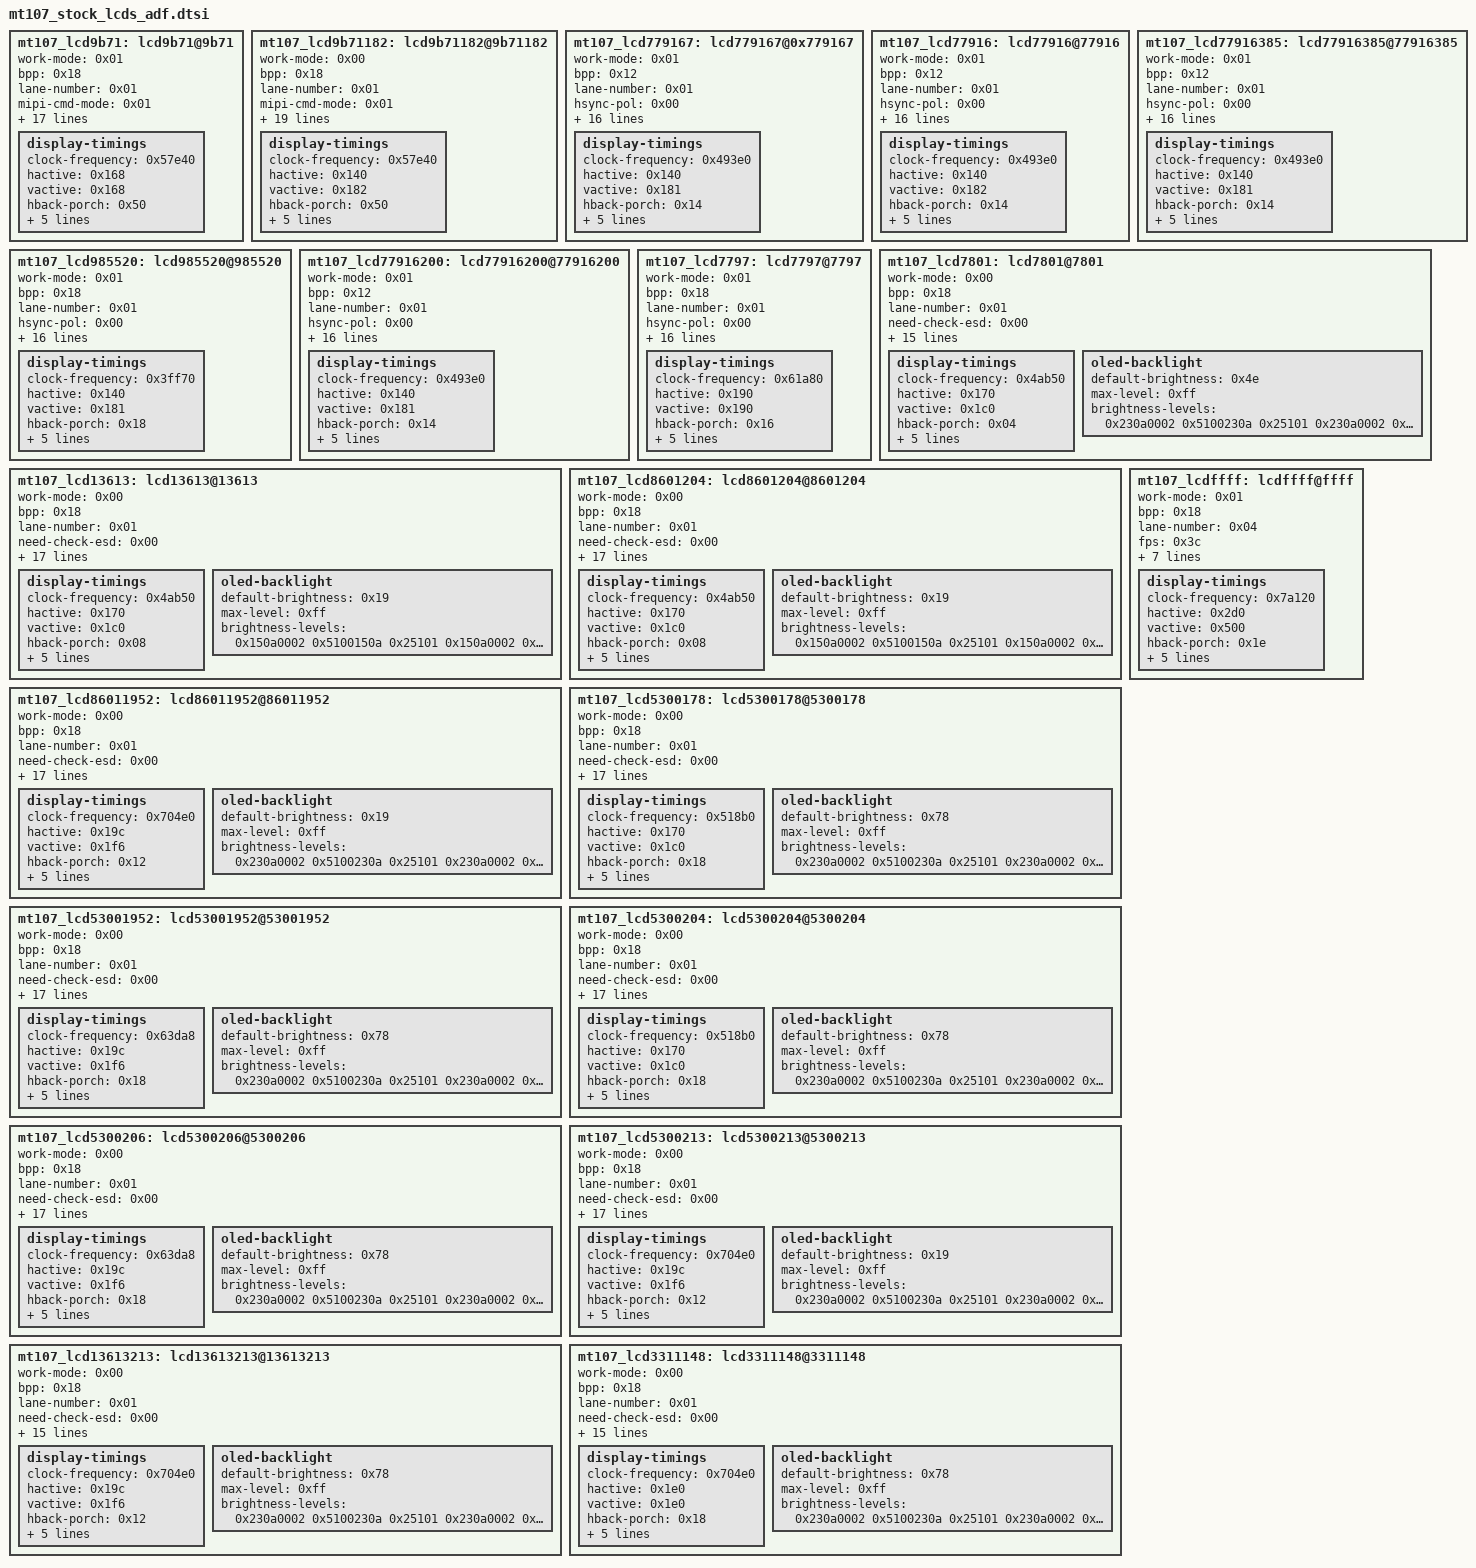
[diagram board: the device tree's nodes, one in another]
// SPDX-License-Identifier: GPL-2.0
/*
 * Stock /lcds panel nodes, generated by devices/stock_lcds_to_dtsi.py
 * from the stock DT; include inside a "lcds" node.
 */

	mt107_lcd9b71: lcd9b71@9b71 {
		work-mode = <0x01>;
		bpp = <0x18>;
		lane-number = <0x01>;
		mipi-cmd-mode = <0x01>;
		hsync-pol = <0x00>;
		vsync-pol = <0x00>;
		de-pol = <0x00>;
		te-pol = <0x00>;
		color-mode-pol = <0x01>;
		shut-down-pol = <0x01>;
		need-check-esd = <0x00>;
		esd-timeout = <0x3e8>;
		fps = <0x3c>;
		panel-name = "lcd_gc9b71_mipi_boe1389";
		power-on-sequence = <0x32 0x01 0x32 0x32 0x00 0x32 0x32 0x01 0xc8>;
		power-off-sequence = <0x32 0x00 0x78>;
		init-data = [05 00 00 01 fe 05 00 00 01 ef 15 00 00 02 80 19 15 00 00 02 81 30 15 00 00 02 82 09 15 00 00 02 83 03 15 00 00 02 84 63 15 00 00 02 89 18 15 00 00 02 8a 40 15 00 00 02 8b 0a 15 00 00 02 3a 07 15 00 00 02 36 00 15 00 00 02 ec 07 39 00 00 08 74 01 68 d8 00 00 4e 00 15 00 00 02 98 3e 15 00 00 02 99 3e 39 00 00 03 a1 01 04 39 00 00 03 a2 01 04 15 00 00 02 cb 02 39 00 00 03 7c b6 24 15 00 00 02 ac 34 15 00 00 02 f6 c8 39 00 00 03 b5 0c 0c 39 00 00 03 eb 01 67 15 00 00 02 b0 81 39 00 00 03 73 10 03 39 00 00 05 60 38 0e 1f 56 39 00 00 05 63 38 10 1f 56 39 00 00 07 64 38 12 72 ea 1f 56 39 00 00 07 66 38 16 72 ee 1f 56 39 00 00 08 68 00 0a ee 0a ee 1c 1c 39 00 00 08 69 00 0a f2 0a f2 1c 1c 39 00 00 21 6e 07 01 1a 00 0b 0b 09 09 13 13 11 11 19 1e 1d 00 00 1d 1e 19 12 12 14 14 0a 0a 0c 0c 00 1a 02 08 39 00 00 08 6c cc 0c cc 84 cc 04 50 15 00 00 02 7d 72 15 00 00 02 35 00 39 00 00 0b 70 02 03 09 07 09 03 09 07 09 03 39 00 00 05 90 06 06 05 06 39 00 00 04 93 45 ff 00 15 00 00 02 c3 10 15 00 00 02 c4 36 15 00 00 02 c9 3f 39 00 00 07 f0 4f 0d 0a 05 00 32 39 00 00 07 f2 4f 0e 09 04 00 31 39 00 00 07 f1 45 d3 7c 2d 2f cf 39 00 00 07 f3 48 d2 7c 2d 2f cf 39 00 00 07 f3 48 d2 7c 2d 2f cf 15 00 00 02 be 11 39 00 00 03 fb 00 00 05 78 00 01 fe 05 78 00 01 ee 05 78 00 01 11 05 78 00 01 29 39 00 00 05 2c 00 00 00 00 39 00 00 05 2c 00 00 00 00];
		sleep-in = [05 0a 00 01 28 05 78 00 01 10];
		sleep-out = [05 78 00 01 11 05 64 00 01 29];

		display-timings {
			clock-frequency = <0x57e40>;
			hactive = <0x168>;
			vactive = <0x168>;
			hback-porch = <0x50>;
			hfront-porch = <0x3c>;
			vback-porch = <0x0c>;
			vfront-porch = <0x08>;
			hsync-len = <0x10>;
			vsync-len = <0x02>;
		};
	};

	mt107_lcd9b71182: lcd9b71182@9b71182 {
		work-mode = <0x00>;
		bpp = <0x18>;
		lane-number = <0x01>;
		mipi-cmd-mode = <0x01>;
		hsync-pol = <0x00>;
		vsync-pol = <0x00>;
		de-pol = <0x00>;
		te-pol = <0x00>;
		color-mode-pol = <0x01>;
		shut-down-pol = <0x01>;
		need-check-esd = <0x00>;
		esd-timeout = <0x7d0>;
		esd-check-reg = <0x0a>;
		esd-return-code = <0x9c>;
		fps = <0x3c>;
		panel-name = "lcd_gc9b71_mipi_boe182";
		power-on-sequence = <0x32 0x01 0x14 0x32 0x00 0x14 0x32 0x01 0x78>;
		power-off-sequence = <0x32 0x00 0x78>;
		init-data = [05 00 00 01 fe 05 00 00 01 ef 15 00 00 02 80 11 15 00 00 02 81 30 15 00 00 02 82 09 15 00 00 02 83 03 15 00 00 02 84 32 15 00 00 02 89 18 15 00 00 02 8a 40 15 00 00 02 8b 0a 15 00 00 02 3a 07 15 00 00 02 36 40 15 00 00 02 ec 07 39 00 00 07 74 01 80 00 00 00 00 15 00 00 02 98 3e 15 00 00 02 99 3e 39 00 00 03 a1 01 04 39 00 00 03 a2 01 04 15 00 00 02 cb 02 39 00 00 03 7c b6 24 15 00 00 02 ac 74 15 00 00 02 f6 80 39 00 00 03 b5 09 09 39 00 00 03 eb 01 81 39 00 00 05 60 38 06 13 56 39 00 00 05 63 38 08 13 56 39 00 00 05 61 3b 1b 58 38 39 00 00 05 62 3b 1b 58 38 39 00 00 07 64 38 0a 73 16 13 56 39 00 00 07 66 38 0b 73 17 13 56 39 00 00 08 68 00 0b 22 0b 22 1c 1c 39 00 00 08 69 00 0b 26 0b 26 1c 1c 39 00 00 03 6a 15 00 39 0a 00 21 6e 08 02 1a 00 12 12 11 11 14 14 13 13 04 19 1e 1d 1d 1e 19 04 0b 0b 0c 0c 09 09 0a 0a 00 1a 01 07 39 00 00 08 6c cc 0c cc 84 cc 04 50 15 00 00 02 7d 72 39 00 00 0b 70 02 03 09 07 09 03 09 07 09 03 39 00 00 05 90 06 06 05 06 39 00 00 04 93 45 ff 00 15 00 00 02 c3 15 15 00 00 02 c4 36 15 00 00 02 c9 3d 39 00 00 07 f0 47 07 0a 0a 00 29 39 00 00 07 f2 47 07 0a 0a 00 29 39 00 00 07 f1 42 91 10 2d 2f 6f 39 00 00 07 f3 42 91 10 2d 2f 6f 39 00 00 05 2a 00 00 01 3f 39 00 00 05 2b 00 00 01 81 05 00 00 01 2c 15 00 00 02 f9 30 15 00 00 02 be 11 39 00 00 03 fb 00 00 15 00 00 03 b4 0a 00 15 00 00 02 35 00 05 00 00 01 fe 05 00 00 01 ef 05 78 00 01 11 05 14 00 01 29 39 00 00 05 2c 00 00 00 00 39 34 00 05 2c 00 00 00 00];
		sleep-in = [05 0a 00 01 28 05 78 00 01 10];
		sleep-out = [05 78 00 01 11 05 64 00 01 29];

		display-timings {
			clock-frequency = <0x57e40>;
			hactive = <0x140>;
			vactive = <0x182>;
			hback-porch = <0x50>;
			hfront-porch = <0x3c>;
			vback-porch = <0x0c>;
			vfront-porch = <0x08>;
			hsync-len = <0x10>;
			vsync-len = <0x02>;
		};
	};

	mt107_lcd779167: lcd779167@0x779167 {
		work-mode = <0x01>;
		bpp = <0x12>;
		lane-number = <0x01>;
		hsync-pol = <0x00>;
		vsync-pol = <0x00>;
		de-pol = <0x00>;
		te-pol = <0x00>;
		color-mode-pol = <0x01>;
		shut-down-pol = <0x01>;
		need-check-esd = <0x00>;
		esd-timeout = <0x3e8>;
		fps = <0x37>;
		panel-name = "lcd_st77916_k7_mipi_boe196";
		power-on-sequence = <0x32 0x01 0x32 0x32 0x00 0x32 0x32 0x01 0x78>;
		power-off-sequence = <0x32 0x00 0x14>;
		init-data = [39 00 00 03 f0 00 08 39 00 00 03 f2 00 08 39 00 00 03 9b 00 51 39 00 00 03 86 00 53 39 00 00 03 f2 00 80 39 00 00 03 f0 00 00 39 00 00 03 f0 00 01 39 00 00 03 f1 00 01 39 00 00 03 b0 00 56 39 00 00 03 b1 00 4d 39 00 00 03 b2 00 24 39 00 00 03 b4 00 66 39 00 00 03 b5 00 44 39 00 00 03 b6 00 8b 39 00 00 03 b7 00 40 39 00 00 03 ba 00 00 39 00 00 03 bb 00 08 39 00 00 03 bc 00 08 39 00 00 03 bd 00 00 39 00 00 03 c0 00 80 39 00 00 03 c1 00 06 39 00 00 03 c2 00 35 39 00 00 03 c3 00 80 39 00 00 03 c4 00 06 39 00 00 03 c5 00 35 39 00 00 03 c6 00 a9 39 00 00 03 c7 00 41 39 00 00 03 c8 00 51 39 00 00 03 c9 00 a9 39 00 00 03 ca 00 41 39 00 00 03 cb 00 51 39 00 00 03 d0 00 d1 39 00 00 03 d1 00 40 39 00 00 03 d2 00 82 39 00 00 04 f5 00 00 a5 39 00 00 03 dd 00 49 39 00 00 03 de 00 49 39 00 00 03 f1 00 10 39 00 00 03 f0 00 00 39 00 00 03 f0 00 02 39 05 00 1d e0 00 f0 00 0a 00 11 00 0c 00 0b 00 08 00 3a 00 54 00 51 00 29 00 16 00 15 00 31 00 34 39 05 00 1d e1 00 f0 00 0a 00 11 00 0b 00 0a 00 07 00 39 00 43 00 4e 00 09 00 15 00 15 00 2e 00 34 39 00 00 03 f0 00 10 39 00 00 03 f3 00 10 39 00 00 03 e0 00 08 39 00 00 03 e1 00 00 39 00 00 03 e2 00 0b 39 00 00 03 e3 00 00 39 00 00 03 e4 00 e0 39 00 00 03 e5 00 06 39 00 00 03 e6 00 21 39 00 00 03 e7 00 10 39 00 00 03 e8 00 8a 39 00 00 03 e9 00 82 39 00 00 03 ea 00 e4 39 00 00 03 eb 00 00 39 00 00 03 ec 00 00 39 00 00 03 ed 00 14 39 00 00 03 ee 00 ff 39 00 00 03 ef 00 00 39 00 00 03 f8 00 ff 39 00 00 03 f9 00 00 39 00 00 03 fa 00 00 39 00 00 03 fb 00 30 39 00 00 03 fc 00 00 39 00 00 03 fd 00 00 39 00 00 03 fe 00 00 39 00 00 03 ff 00 00 39 00 00 03 60 00 50 39 00 00 03 61 00 02 39 00 00 03 62 00 0b 39 00 00 03 63 00 50 39 00 00 03 64 00 04 39 00 00 03 65 00 0b 39 00 00 03 66 00 53 39 00 00 03 67 00 08 39 00 00 03 68 00 0b 39 00 00 03 69 00 53 39 00 00 03 6a 00 0a 39 00 00 03 6b 00 0b 39 00 00 03 70 00 50 39 00 00 03 71 00 01 39 00 00 03 72 00 0b 39 00 00 03 73 00 50 39 00 00 03 74 00 03 39 00 00 03 75 00 0b 39 00 00 03 76 00 53 39 00 00 03 77 00 07 39 00 00 03 78 00 0b 39 00 00 03 79 00 53 39 00 00 03 7a 00 09 39 00 00 03 7b 00 0b 39 00 00 03 80 00 58 39 00 00 03 81 00 00 39 00 00 03 82 00 04 39 00 00 03 83 00 03 39 00 00 03 84 00 0c 39 00 00 03 85 00 00 39 00 00 03 86 00 00 39 00 00 03 87 00 00 39 00 00 03 88 00 58 39 00 00 03 89 00 00 39 00 00 03 8a 00 06 39 00 00 03 8b 00 03 39 00 00 03 8c 00 0e 39 00 00 03 8d 00 00 39 00 00 03 8e 00 00 39 00 00 03 8f 00 00 39 00 00 03 90 00 58 39 00 00 03 91 00 00 39 00 00 03 92 00 08 39 00 00 03 93 00 03 39 00 00 03 94 00 10 39 00 00 03 95 00 00 39 00 00 03 96 00 00 39 00 00 03 97 00 00 39 00 00 03 98 00 58 39 00 00 03 99 00 00 39 00 00 03 9a 00 0a 39 00 00 03 9b 00 03 39 00 00 03 9c 00 12 39 00 00 03 9d 00 00 39 00 00 03 9e 00 00 39 00 00 03 9f 00 00 39 00 00 03 a0 00 58 39 00 00 03 a1 00 00 39 00 00 03 a2 00 03 39 00 00 03 a3 00 03 39 00 00 03 a4 00 0b 39 00 00 03 a5 00 00 39 00 00 03 a6 00 00 39 00 00 03 a7 00 00 39 00 00 03 a8 00 58 39 00 00 03 a9 00 00 39 00 00 03 aa 00 05 39 00 00 03 ab 00 03 39 00 00 03 ac 00 0d 39 00 00 03 ad 00 00 39 00 00 03 ae 00 00 39 00 00 03 af 00 00 39 00 00 03 b0 00 58 39 00 00 03 b1 00 00 39 00 00 03 b2 00 07 39 00 00 03 b3 00 03 39 00 00 03 b4 00 0f 39 00 00 03 b5 00 00 39 00 00 03 b6 00 00 39 00 00 03 b7 00 00 39 00 00 03 b8 00 58 39 00 00 03 b9 00 00 39 00 00 03 ba 00 09 39 00 00 03 bb 00 03 39 00 00 03 bc 00 11 39 00 00 03 bd 00 00 39 00 00 03 be 00 00 39 00 00 03 bf 00 00 39 00 00 03 c0 00 03 39 00 00 03 c1 00 12 39 00 00 03 c2 00 aa 39 00 00 03 c3 00 30 39 00 00 03 c4 00 21 39 00 00 03 c5 00 bb 39 00 00 03 c6 00 64 39 00 00 03 c7 00 55 39 00 00 03 c8 00 46 39 00 00 03 c9 00 77 39 00 00 03 d0 00 03 39 00 00 03 d1 00 12 39 00 00 03 d2 00 aa 39 00 00 03 d3 00 30 39 00 00 03 d4 00 21 39 00 00 03 d5 00 bb 39 00 00 03 d6 00 64 39 00 00 03 d7 00 55 39 00 00 03 d8 00 46 39 00 00 03 d9 00 77 39 00 00 03 f3 00 01 39 00 00 03 f0 00 00 39 00 00 03 f0 00 01 39 00 00 03 f1 00 01 39 00 00 03 a0 00 0b 39 00 00 03 a3 00 2a 39 0a 00 03 a5 00 c3 39 00 00 03 a3 00 2b 39 0a 00 03 a5 00 c3 39 00 00 03 a3 00 2c 39 0a 00 03 a5 00 c3 39 00 00 03 a3 00 2d 39 0a 00 03 a5 00 c3 39 00 00 03 a3 00 2e 39 0a 00 03 a5 00 c3 39 00 00 03 a3 00 2f 39 0a 00 03 a5 00 c3 39 00 00 03 a3 00 30 39 0a 00 03 a5 00 c3 39 00 00 03 a3 00 31 39 0a 00 03 a5 00 c3 39 00 00 03 a3 00 32 39 0a 00 03 a5 00 c3 39 00 00 03 a3 00 33 39 0a 00 03 a5 00 c3 39 00 00 03 a0 00 09 39 00 00 03 f1 00 10 39 0a 00 03 f0 00 00 39 00 00 09 2a 00 00 00 00 00 01 00 3f 39 00 00 09 2b 00 01 00 81 00 01 00 81 39 00 00 03 4d 00 00 39 00 00 03 4e 00 00 39 00 00 03 4f 00 00 39 00 00 03 4c 00 01 39 0a 00 03 4c 00 00 39 00 00 09 2a 00 00 00 00 00 01 00 3f 39 00 00 09 2b 00 00 00 00 00 01 00 80 39 00 00 01 21 39 00 00 03 3a 00 66 39 78 00 01 11 39 2a 00 01 29 39 32 00 01 00];
		sleep-in = [13 0a 00 01 28 13 78 00 01 10];
		sleep-out = [13 78 00 01 11 13 64 00 01 29];

		display-timings {
			clock-frequency = <0x493e0>;
			hactive = <0x140>;
			vactive = <0x181>;
			hback-porch = <0x14>;
			hfront-porch = <0x1e>;
			vback-porch = <0x10>;
			vfront-porch = <0x10>;
			hsync-len = <0x0a>;
			vsync-len = <0x02>;
		};
	};

	mt107_lcd77916: lcd77916@77916 {
		work-mode = <0x01>;
		bpp = <0x12>;
		lane-number = <0x01>;
		hsync-pol = <0x00>;
		vsync-pol = <0x00>;
		de-pol = <0x00>;
		te-pol = <0x00>;
		color-mode-pol = <0x01>;
		shut-down-pol = <0x01>;
		need-check-esd = <0x00>;
		esd-timeout = <0x3e8>;
		fps = <0x32>;
		panel-name = "lcd_st77916_mipi_boe196";
		power-on-sequence = <0x32 0x01 0x32 0x32 0x00 0x32 0x32 0x01 0x78>;
		power-off-sequence = <0x32 0x00 0x14>;
		init-data = <0x39000003 0xf0000839 0x3f2 0x83900 0x39b00 0x51390000 0x3860053 0x39000003 0xf2008039 0x3f0 0x3900 0x3f000 0x1390000 0x3f10001 0x39000003 0xb0005e39 0x3b1 0x3d3900 0x3b200 0x30390000 0x3b40027 0x39000003 0xb5003439 0x3b6 0xa53900 0x3b700 0x20390000 0x3ba0000 0x39000003 0xbb000839 0x3bc 0x83900 0x3bd00 0x390000 0x3c00080 0x39000003 0xc1000b39 0x3c2 0x343900 0x3c300 0x80390000 0x3c4000b 0x39000003 0xc5003439 0x3c6 0xa93900 0x3c700 0x41390000 0x3c80051 0x39000003 0xc900a939 0x3ca 0x413900 0x3cb00 0x51390000 0x3d000d1 0x39000003 0xd1004039 0x3d2 0x833900 0x4f500 0xa53900 0x3dd00 0x2f390000 0x3de002f 0x39000003 0xf1001039 0x3f0 0x3900 0x3f000 0x2390500 0x1de000f0 0xa0010 0xa0009 0x150037 0x33004f 0x380014 0x140032 0x363905 0x1de100 0xf0000900 0xf000a00 0x9002500 0x37003300 0x4f003700 0x13001400 0x31003539 0x3f0 0x103900 0x3f300 0x10390000 0x3e0000c 0x39000003 0xe1000039 0x3e2 0x3900 0x3e300 0x390000 0x3e400e0 0x39000003 0xe5000639 0x3e6 0x213900 0x3e700 0x10390000 0x3e80085 0x39000003 0xe9008339 0x3ea 0x163900 0x3eb00 0x390000 0x3ec0000 0x39000003 0xed001439 0x3ee 0xff3900 0x3ef00 0x390000 0x3f800ff 0x39000003 0xf9000039 0x3fa 0x3900 0x3fb00 0x30390000 0x3fc0000 0x39000003 0xfd000039 0x3fe 0x3900 0x3ff00 0x390000 0x3600043 0x39000003 0x61001a39 0x362 0x403900 0x36300 0x40390000 0x3640002 0x39000003 0x65000039 0x366 0x403900 0x36700 0x3390000 0x3680000 0x39000003 0x69000039 0x36a 0x3900 0x36b00 0x390000 0x3700043 0x39000003 0x71001a39 0x372 0x403900 0x37300 0x40390000 0x3740002 0x39000003 0x75000039 0x376 0x403900 0x37700 0x3390000 0x3780000 0x39000003 0x79000039 0x37a 0x3900 0x37b00 0x390000 0x3800048 0x39000003 0x81000039 0x382 0x73900 0x38300 0x3390000 0x3840017 0x39000003 0x85000039 0x386 0x3900 0x38700 0x390000 0x3880048 0x39000003 0x89000039 0x38a 0x93900 0x38b00 0x3390000 0x38c0019 0x39000003 0x8d000039 0x38e 0x3900 0x38f00 0x390000 0x3900048 0x39000003 0x91000039 0x392 0xb3900 0x39300 0x3390000 0x3940013 0x39000003 0x95000039 0x396 0x3900 0x39700 0x390000 0x3980048 0x39000003 0x99000039 0x39a 0xd3900 0x39b00 0x3390000 0x39c0015 0x39000003 0x9d000039 0x39e 0x3900 0x39f00 0x390000 0x3a00048 0x39000003 0xa1000039 0x3a2 0x63900 0x3a300 0x3390000 0x3a40016 0x39000003 0xa5000039 0x3a6 0x3900 0x3a700 0x390000 0x3a80048 0x39000003 0xa9000039 0x3aa 0x83900 0x3ab00 0x3390000 0x3ac0018 0x39000003 0xad000039 0x3ae 0x3900 0x3af00 0x390000 0x3b00048 0x39000003 0xb1000039 0x3b2 0xa3900 0x3b300 0x3390000 0x3b40012 0x39000003 0xb5000039 0x3b6 0x3900 0x3b700 0x390000 0x3b80048 0x39000003 0xb9000039 0x3ba 0xc3900 0x3bb00 0x3390000 0x3bc0014 0x39000003 0xbd000039 0x3be 0x3900 0x3bf00 0x390000 0x3c00045 0x39000003 0xc1005439 0x3c2 0x673900 0x3c300 0x76390000 0x3c40088 0x39000003 0xc500aa39 0x3c6 0x223900 0x3c700 0xbb390000 0x3c80000 0x39000003 0xc9009939 0x3d0 0x453900 0x3d100 0x54390000 0x3d20067 0x39000003 0xd3007639 0x3d4 0x883900 0x3d500 0xaa390000 0x3d60011 0x39000003 0xd700bb39 0x3d8 0x3900 0x3d900 0x99390000 0x3f30001 0x39000003 0xf0000039 0x3f0 0x13900 0x3f100 0x1390000 0x3a0000b 0x39000003 0xa3002a39 0xa0003a5 0xc33900 0x3a300 0x2b390a00 0x3a500c3 0x39000003 0xa3002c39 0xa0003a5 0xc33900 0x3a300 0x2d390a00 0x3a500c3 0x39000003 0xa3002e39 0xa0003a5 0xc33900 0x3a300 0x2f390a00 0x3a500c3 0x39000003 0xa3003039 0xa0003a5 0xc33900 0x3a300 0x31390a00 0x3a500c3 0x39000003 0xa3003239 0xa0003a5 0xc33900 0x3a300 0x33390a00 0x3a500c3 0x39000003 0xa0000939 0x3f1 0x10390a 0x3f000 0x390000 0x92a0000 0x01 0x3f3900 0x92b00 0x1008200 0x1008239 0x34d 0x3900 0x34e00 0x390000 0x34f0000 0x390a0003 0x4c000139 0x92a 0x00 0x1003f 0x39000009 0x2b000000 0x100 0x81050000 0x1213900 0x33a00 0x66057800 0x111052a 0x12905 0x32000100>;
		sleep-in = [05 0a 00 01 28 05 78 00 01 10];
		sleep-out = [05 78 00 01 11 05 64 00 01 29];

		display-timings {
			clock-frequency = <0x493e0>;
			hactive = <0x140>;
			vactive = <0x182>;
			hback-porch = <0x14>;
			hfront-porch = <0x1e>;
			vback-porch = <0x10>;
			vfront-porch = <0x10>;
			hsync-len = <0x0a>;
			vsync-len = <0x02>;
		};
	};

	mt107_lcd77916385: lcd77916385@77916385 {
		work-mode = <0x01>;
		bpp = <0x12>;
		lane-number = <0x01>;
		hsync-pol = <0x00>;
		vsync-pol = <0x00>;
		de-pol = <0x00>;
		te-pol = <0x00>;
		color-mode-pol = <0x01>;
		shut-down-pol = <0x01>;
		need-check-esd = <0x00>;
		esd-timeout = <0x3e8>;
		fps = <0x37>;
		panel-name = "lcd_st77916_mipi_cto200";
		power-on-sequence = <0x32 0x01 0x32 0x32 0x00 0x32 0x32 0x01 0x78>;
		power-off-sequence = <0x32 0x00 0x14>;
		init-data = [39 00 00 03 f0 00 08 39 00 00 03 f2 00 08 39 00 00 03 9b 00 51 39 00 00 03 86 00 53 39 00 00 03 f2 00 80 39 00 00 03 f0 00 00 39 00 00 03 f0 00 28 39 00 00 03 f2 00 28 39 00 00 03 83 00 e0 39 00 00 03 84 00 61 39 00 00 03 f2 00 82 39 00 00 03 f0 00 00 39 00 00 03 f0 00 01 39 00 00 03 f1 00 01 39 00 00 03 70 00 bf 39 00 00 03 b0 00 56 39 00 00 03 b1 00 4d 39 00 00 03 b2 00 24 39 00 00 03 b4 00 66 39 00 00 03 b5 00 44 39 00 00 03 b6 00 8b 39 00 00 03 b7 00 40 39 00 00 03 b8 00 05 39 00 00 03 ba 00 00 39 00 00 03 bb 00 08 39 00 00 03 bc 00 08 39 00 00 03 bd 00 00 39 00 00 03 c0 00 80 39 00 00 03 c1 00 08 39 00 00 03 c2 00 35 39 00 00 03 c3 00 80 39 00 00 03 c4 00 08 39 00 00 03 c5 00 35 39 00 00 03 c6 00 a9 39 00 00 03 c7 00 41 39 00 00 03 c8 00 51 39 00 00 03 c9 00 a9 39 00 00 03 ca 00 41 39 00 00 03 cb 00 51 39 00 00 03 d0 00 d1 39 00 00 03 d1 00 40 39 00 00 03 d2 00 82 39 00 00 04 f5 00 00 a5 39 00 00 03 dd 00 49 39 00 00 03 de 00 49 39 00 00 03 f1 00 10 39 00 00 03 f0 00 00 39 00 00 03 f0 00 02 39 05 00 1d e0 00 f0 00 0a 00 11 00 0c 00 0b 00 08 00 3a 00 54 00 51 00 29 00 16 00 15 00 31 00 34 39 05 00 1d e1 00 f0 00 0a 00 11 00 0b 00 0a 00 07 00 39 00 43 00 4e 00 09 00 15 00 15 00 2e 00 34 39 00 00 03 f0 00 10 39 00 00 03 f3 00 10 39 00 00 03 e0 00 08 39 00 00 03 e1 00 00 39 00 00 03 e2 00 0b 39 00 00 03 e3 00 00 39 00 00 03 e4 00 e0 39 00 00 03 e5 00 06 39 00 00 03 e6 00 21 39 00 00 03 e7 00 10 39 00 00 03 e8 00 8a 39 00 00 03 e9 00 82 39 00 00 03 ea 00 e4 39 00 00 03 eb 00 00 39 00 00 03 ec 00 00 39 00 00 03 ed 00 14 39 00 00 03 ee 00 ff 39 00 00 03 ef 00 00 39 00 00 03 f8 00 ff 39 00 00 03 f9 00 00 39 00 00 03 fa 00 00 39 00 00 03 fb 00 30 39 00 00 03 fc 00 00 39 00 00 03 fd 00 00 39 00 00 03 fe 00 00 39 00 00 03 ff 00 00 39 00 00 03 60 00 50 39 00 00 03 61 00 02 39 00 00 03 62 00 0b 39 00 00 03 63 00 50 39 00 00 03 64 00 04 39 00 00 03 65 00 0b 39 00 00 03 66 00 53 39 00 00 03 67 00 08 39 00 00 03 68 00 0b 39 00 00 03 69 00 53 39 00 00 03 6a 00 0a 39 00 00 03 6b 00 0b 39 00 00 03 70 00 50 39 00 00 03 71 00 01 39 00 00 03 72 00 0b 39 00 00 03 73 00 50 39 00 00 03 74 00 03 39 00 00 03 75 00 0b 39 00 00 03 76 00 53 39 00 00 03 77 00 07 39 00 00 03 78 00 0b 39 00 00 03 79 00 53 39 00 00 03 7a 00 09 39 00 00 03 7b 00 0b 39 00 00 03 80 00 58 39 00 00 03 81 00 00 39 00 00 03 82 00 04 39 00 00 03 83 00 03 39 00 00 03 84 00 0c 39 00 00 03 85 00 00 39 00 00 03 86 00 00 39 00 00 03 87 00 00 39 00 00 03 88 00 58 39 00 00 03 89 00 00 39 00 00 03 8a 00 06 39 00 00 03 8b 00 03 39 00 00 03 8c 00 0e 39 00 00 03 8d 00 00 39 00 00 03 8e 00 00 39 00 00 03 8f 00 00 39 00 00 03 90 00 58 39 00 00 03 91 00 00 39 00 00 03 92 00 08 39 00 00 03 93 00 03 39 00 00 03 94 00 10 39 00 00 03 95 00 00 39 00 00 03 96 00 00 39 00 00 03 97 00 00 39 00 00 03 98 00 58 39 00 00 03 99 00 00 39 00 00 03 9a 00 0a 39 00 00 03 9b 00 03 39 00 00 03 9c 00 12 39 00 00 03 9d 00 00 39 00 00 03 9e 00 00 39 00 00 03 9f 00 00 39 00 00 03 a0 00 58 39 00 00 03 a1 00 00 39 00 00 03 a2 00 03 39 00 00 03 a3 00 03 39 00 00 03 a4 00 0b 39 00 00 03 a5 00 00 39 00 00 03 a6 00 00 39 00 00 03 a7 00 00 39 00 00 03 a8 00 58 39 00 00 03 a9 00 00 39 00 00 03 aa 00 05 39 00 00 03 ab 00 03 39 00 00 03 ac 00 0d 39 00 00 03 ad 00 00 39 00 00 03 ae 00 00 39 00 00 03 af 00 00 39 00 00 03 b0 00 58 39 00 00 03 b1 00 00 39 00 00 03 b2 00 07 39 00 00 03 b3 00 03 39 00 00 03 b4 00 0f 39 00 00 03 b5 00 00 39 00 00 03 b6 00 00 39 00 00 03 b7 00 00 39 00 00 03 b8 00 58 39 00 00 03 b9 00 00 39 00 00 03 ba 00 09 39 00 00 03 bb 00 03 39 00 00 03 bc 00 11 39 00 00 03 bd 00 00 39 00 00 03 be 00 00 39 00 00 03 bf 00 00 39 00 00 03 c0 00 03 39 00 00 03 c1 00 12 39 00 00 03 c2 00 aa 39 00 00 03 c3 00 30 39 00 00 03 c4 00 21 39 00 00 03 c5 00 bb 39 00 00 03 c6 00 64 39 00 00 03 c7 00 55 39 00 00 03 c8 00 46 39 00 00 03 c9 00 77 39 00 00 03 d0 00 03 39 00 00 03 d1 00 12 39 00 00 03 d2 00 aa 39 00 00 03 d3 00 30 39 00 00 03 d4 00 21 39 00 00 03 d5 00 bb 39 00 00 03 d6 00 64 39 00 00 03 d7 00 55 39 00 00 03 d8 00 46 39 00 00 03 d9 00 77 39 00 00 03 f3 00 01 39 00 00 03 f0 00 00 39 00 00 03 f0 00 01 39 00 00 03 f1 00 01 39 00 00 03 a0 00 0b 39 00 00 03 a3 00 2a 39 0a 00 03 a5 00 c3 39 00 00 03 a3 00 2b 39 0a 00 03 a5 00 c3 39 00 00 03 a3 00 2c 39 0a 00 03 a5 00 c3 39 00 00 03 a3 00 2d 39 0a 00 03 a5 00 c3 39 00 00 03 a3 00 2e 39 0a 00 03 a5 00 c3 39 00 00 03 a3 00 2f 39 0a 00 03 a5 00 c3 39 00 00 03 a3 00 30 39 0a 00 03 a5 00 c3 39 00 00 03 a3 00 31 39 0a 00 03 a5 00 c3 39 00 00 03 a3 00 32 39 0a 00 03 a5 00 c3 39 00 00 03 a3 00 33 39 0a 00 03 a5 00 c3 39 00 00 03 a0 00 09 39 00 00 03 f1 00 10 39 0a 00 03 f0 00 00 39 00 00 09 2a 00 00 00 00 00 01 00 3f 39 00 00 09 2b 00 01 00 81 00 01 00 81 39 00 00 03 4d 00 00 39 00 00 03 4e 00 00 39 00 00 03 4f 00 00 39 0a 00 03 4c 00 01 39 00 00 03 4c 00 00 39 00 00 09 2a 00 00 00 00 00 01 00 3f 39 00 00 09 2b 00 00 00 00 00 01 00 80 05 00 00 01 21 39 00 00 03 3a 00 66 05 78 00 01 11 05 2a 00 01 29 05 32 00 01 00];
		sleep-in = [05 0a 00 01 28 05 78 00 01 10];
		sleep-out = [05 78 00 01 11 05 64 00 01 29];

		display-timings {
			clock-frequency = <0x493e0>;
			hactive = <0x140>;
			vactive = <0x181>;
			hback-porch = <0x14>;
			hfront-porch = <0x1e>;
			vback-porch = <0x10>;
			vfront-porch = <0x10>;
			hsync-len = <0x0a>;
			vsync-len = <0x02>;
		};
	};

	mt107_lcd985520: lcd985520@985520 {
		work-mode = <0x01>;
		bpp = <0x18>;
		lane-number = <0x01>;
		hsync-pol = <0x00>;
		vsync-pol = <0x00>;
		de-pol = <0x00>;
		te-pol = <0x00>;
		color-mode-pol = <0x01>;
		shut-down-pol = <0x01>;
		need-check-esd = <0x00>;
		esd-timeout = <0x3e8>;
		fps = <0x3c>;
		panel-name = "lcd_jd9855_oled_cto20_mipi";
		power-on-sequence = <0x32 0x01 0x32 0x32 0x00 0x32 0x32 0x01 0x78>;
		power-off-sequence = <0x32 0x00 0x14>;
		init-data = [23 00 00 02 de 00 29 00 00 03 df 98 55 23 00 00 02 b2 2f 29 00 00 05 b7 01 33 01 5b 29 00 00 07 bb 1b 64 c2 33 3e f3 29 00 00 05 bc 00 18 f3 c0 29 00 00 03 c0 22 c1 29 00 00 0c c3 00 02 2a 0b 08 47 08 04 62 30 30 29 00 00 0c c4 40 00 a8 81 3f 07 04 16 3f 07 04 29 05 00 21 c8 3f 31 28 23 22 23 1d 1d 1b 1b 17 0d 09 06 02 02 3f 31 28 23 22 23 1d 1d 1b 1b 17 0d 09 06 02 02 29 00 00 03 d3 28 13 29 00 00 03 d7 1b 30 29 00 00 07 d9 00 00 ff 00 f0 00 23 00 00 02 de 01 29 00 00 09 b7 13 e7 64 39 06 36 18 18 23 00 00 02 be 00 29 00 00 05 c1 00 4a 90 08 29 00 00 05 c2 00 16 da e7 29 00 00 07 c7 00 00 02 7c 02 7c 29 00 00 07 c8 00 00 03 01 39 0a 29 00 00 06 c9 12 10 1f 00 02 29 00 00 06 ca 1e 04 06 08 0a 29 00 00 06 cb 13 11 1f 01 03 29 00 00 06 cc 1e 05 07 09 0b 29 00 00 06 cd 01 03 1f 13 11 29 00 00 06 ce 1e 09 07 05 0b 29 00 00 06 cf 00 02 1f 12 10 29 00 00 06 d0 1e 08 06 04 0a 29 00 00 06 d1 04 30 bf 0a 30 29 00 00 07 d3 3c 05 06 01 00 00 23 00 00 02 d4 07 29 00 00 08 d5 10 10 07 07 0f 94 26 29 00 00 04 d6 00 00 40 29 00 00 08 d7 03 8f 20 00 07 00 c0 23 00 00 02 de 02 23 00 00 02 b6 1c 23 00 00 02 de 00 23 00 00 02 4d 00 23 00 00 02 4e 00 23 00 00 02 4f 00 23 0a 00 02 4c 01 23 00 00 02 4c 00 29 00 00 05 2a 00 00 01 3f 29 00 00 05 2b 00 00 01 80 23 00 00 02 35 00 23 00 00 02 3a 77 13 78 00 01 11 13 0a 00 01 29];
		sleep-in = [05 0a 00 01 28 05 78 00 01 10];
		sleep-out = [05 78 00 01 11 05 64 00 01 29];

		display-timings {
			clock-frequency = <0x3ff70>;
			hactive = <0x140>;
			vactive = <0x181>;
			hback-porch = <0x18>;
			hfront-porch = <0x20>;
			vback-porch = <0x04>;
			vfront-porch = <0x08>;
			hsync-len = <0x04>;
			vsync-len = <0x02>;
		};
	};

	mt107_lcd77916200: lcd77916200@77916200 {
		work-mode = <0x01>;
		bpp = <0x12>;
		lane-number = <0x01>;
		hsync-pol = <0x00>;
		vsync-pol = <0x00>;
		de-pol = <0x00>;
		te-pol = <0x00>;
		color-mode-pol = <0x01>;
		shut-down-pol = <0x01>;
		need-check-esd = <0x00>;
		esd-timeout = <0x3e8>;
		fps = <0x37>;
		panel-name = "lcd_st77916_mipi_boe200";
		power-on-sequence = <0x32 0x01 0x32 0x32 0x00 0x32 0x32 0x01 0x78>;
		power-off-sequence = <0x32 0x00 0x14>;
		init-data = [39 00 00 03 f0 00 28 39 00 00 03 f2 00 28 39 00 00 03 7c 00 d1 39 00 00 03 83 00 e0 39 00 00 03 84 00 61 39 00 00 03 f2 00 82 39 00 00 03 f0 00 00 39 00 00 03 f0 00 01 39 00 00 03 f1 00 01 39 00 00 03 b0 00 4b 39 00 00 03 b1 00 40 39 00 00 03 b2 00 25 39 00 00 03 b4 00 44 39 00 00 03 b5 00 34 39 00 00 03 b6 00 a4 39 00 00 03 b7 00 30 39 00 00 03 ba 00 00 39 00 00 03 bb 00 08 39 00 00 03 bc 00 08 39 00 00 03 bd 00 00 39 00 00 03 c0 00 80 39 00 00 03 c1 00 0b 39 00 00 03 c2 00 35 39 00 00 03 c3 00 80 39 00 00 03 c4 00 0b 39 00 00 03 c5 00 35 39 00 00 03 c6 00 a9 39 00 00 03 c7 00 41 39 00 00 03 c8 00 01 39 00 00 03 c9 00 a9 39 00 00 03 ca 00 41 39 00 00 03 cb 00 01 39 00 00 03 d0 00 d1 39 00 00 03 d1 00 40 39 00 00 03 d2 00 81 39 00 00 04 f5 00 00 a5 39 00 00 03 f1 00 10 39 00 00 03 f0 00 00 39 00 00 03 f0 00 02 39 05 00 1d e0 00 f0 00 09 00 0f 00 0a 00 0a 00 17 00 36 00 44 00 4d 00 38 00 13 00 14 00 2f 00 34 39 05 00 1d e1 00 f0 00 09 00 0f 00 0a 00 09 00 06 00 35 00 33 00 4c 00 37 00 13 00 14 00 2f 00 34 39 00 00 03 f0 00 10 39 00 00 03 f3 00 10 39 00 00 03 e0 00 0d 39 00 00 03 e1 00 00 39 00 00 03 e2 00 00 39 00 00 03 e3 00 00 39 00 00 03 e4 00 e0 39 00 00 03 e5 00 06 39 00 00 03 e6 00 21 39 00 00 03 e7 00 00 39 00 00 03 e8 00 85 39 00 00 03 e9 00 62 39 00 00 03 ea 00 dc 39 00 00 03 eb 00 00 39 00 00 03 ec 00 20 39 00 00 03 ed 00 14 39 00 00 03 ee 00 ff 39 00 00 03 ef 00 00 39 00 00 03 f8 00 ff 39 00 00 03 f9 00 00 39 00 00 03 fa 00 00 39 00 00 03 fb 00 30 39 00 00 03 fc 00 00 39 00 00 03 fd 00 00 39 00 00 03 fe 00 00 39 00 00 03 ff 00 00 39 00 00 03 60 00 20 39 00 00 03 61 00 02 39 00 00 03 62 00 80 39 00 00 03 63 00 40 39 00 00 03 64 00 06 39 00 00 03 65 00 00 39 00 00 03 66 00 00 39 00 00 03 67 00 00 39 00 00 03 68 00 00 39 00 00 03 69 00 23 39 00 00 03 6a 00 15 39 00 00 03 6b 00 00 39 00 00 03 70 00 20 39 00 00 03 71 00 02 39 00 00 03 72 00 80 39 00 00 03 73 00 40 39 00 00 03 74 00 05 39 00 00 03 75 00 00 39 00 00 03 76 00 00 39 00 00 03 77 00 00 39 00 00 03 78 00 00 39 00 00 03 79 00 23 39 00 00 03 7a 00 15 39 00 00 03 7b 00 00 39 00 00 03 80 00 48 39 00 00 03 81 00 00 39 00 00 03 82 00 08 39 00 00 03 83 00 03 39 00 00 03 84 00 18 39 00 00 03 85 00 00 39 00 00 03 86 00 00 39 00 00 03 87 00 00 39 00 00 03 88 00 48 39 00 00 03 89 00 00 39 00 00 03 8a 00 0a 39 00 00 03 8b 00 03 39 00 00 03 8c 00 12 39 00 00 03 8d 00 00 39 00 00 03 8e 00 00 39 00 00 03 8f 00 00 39 00 00 03 90 00 48 39 00 00 03 91 00 00 39 00 00 03 92 00 0c 39 00 00 03 93 00 03 39 00 00 03 94 00 14 39 00 00 03 95 00 00 39 00 00 03 96 00 00 39 00 00 03 97 00 00 39 00 00 03 98 00 48 39 00 00 03 99 00 00 39 00 00 03 9a 00 0e 39 00 00 03 9b 00 03 39 00 00 03 9c 00 16 39 00 00 03 9d 00 00 39 00 00 03 9e 00 00 39 00 00 03 9f 00 00 39 00 00 03 a0 00 48 39 00 00 03 a1 00 00 39 00 00 03 a2 00 07 39 00 00 03 a3 00 03 39 00 00 03 a4 00 17 39 00 00 03 a5 00 00 39 00 00 03 a6 00 00 39 00 00 03 a7 00 00 39 00 00 03 a8 00 48 39 00 00 03 a9 00 00 39 00 00 03 aa 00 09 39 00 00 03 ab 00 03 39 00 00 03 ac 00 11 39 00 00 03 ad 00 00 39 00 00 03 ae 00 00 39 00 00 03 af 00 00 39 00 00 03 b0 00 48 39 00 00 03 b1 00 00 39 00 00 03 b2 00 0b 39 00 00 03 b3 00 03 39 00 00 03 b4 00 13 39 00 00 03 b5 00 00 39 00 00 03 b6 00 00 39 00 00 03 b7 00 00 39 00 00 03 b8 00 48 39 00 00 03 b9 00 00 39 00 00 03 ba 00 0d 39 00 00 03 bb 00 03 39 00 00 03 bc 00 15 39 00 00 03 bd 00 00 39 00 00 03 be 00 00 39 00 00 03 bf 00 00 39 00 00 03 c0 00 75 39 00 00 03 c1 00 44 39 00 00 03 c2 00 57 39 00 00 03 c3 00 66 39 00 00 03 c4 00 aa 39 00 00 03 c5 00 11 39 00 00 03 c6 00 00 39 00 00 03 c7 00 88 39 00 00 03 c8 00 99 39 00 00 03 c9 00 bb 39 00 00 03 d0 00 75 39 00 00 03 d1 00 44 39 00 00 03 d2 00 57 39 00 00 03 d3 00 66 39 00 00 03 d4 00 aa 39 00 00 03 d5 00 11 39 00 00 03 d6 00 00 39 00 00 03 d7 00 88 39 00 00 03 d8 00 99 39 00 00 03 d9 00 bb 39 00 00 03 f3 00 01 39 00 00 03 f0 00 00 05 00 00 01 21 39 00 00 03 3a 00 66 05 78 00 01 11 05 2a 00 01 29 05 32 00 01 00];
		sleep-in = [05 0a 00 01 28 05 78 00 01 10];
		sleep-out = [05 78 00 01 11 05 64 00 01 29];

		display-timings {
			clock-frequency = <0x493e0>;
			hactive = <0x140>;
			vactive = <0x181>;
			hback-porch = <0x14>;
			hfront-porch = <0x1e>;
			vback-porch = <0x10>;
			vfront-porch = <0x10>;
			hsync-len = <0x0a>;
			vsync-len = <0x02>;
		};
	};

	mt107_lcd7797: lcd7797@7797 {
		work-mode = <0x01>;
		bpp = <0x18>;
		lane-number = <0x01>;
		hsync-pol = <0x00>;
		vsync-pol = <0x00>;
		de-pol = <0x00>;
		te-pol = <0x00>;
		color-mode-pol = <0x01>;
		shut-down-pol = <0x01>;
		need-check-esd = <0x00>;
		esd-timeout = <0x3e8>;
		fps = <0x3c>;
		panel-name = "lcd_st7797_mipi";
		power-on-sequence = <0x32 0x01 0x05 0x32 0x00 0x05 0x32 0x01 0x14>;
		power-off-sequence = <0x32 0x00 0x14>;
		init-data = [23 00 00 02 f0 c3 23 00 00 02 f0 96 23 00 00 02 f0 a5 29 00 00 05 c1 bb 02 0f 0b 29 00 00 05 c2 bb 02 0f 0b 29 00 00 05 c3 11 03 24 01 29 00 00 05 c4 11 03 24 01 23 00 00 02 c5 2e 29 00 00 0f e0 f0 05 0a 0c 0a 07 34 73 4b 0e 1b 19 29 2a 29 00 00 0f e1 f0 05 0a 0c 0a 06 33 03 4c 0e 1c 1a 29 2a 29 00 00 03 e4 c8 20 29 00 00 0d e5 0f f5 00 11 22 25 10 77 77 77 44 44 29 00 00 0d e6 0f f5 00 11 22 25 10 22 22 22 22 22 29 00 00 08 e7 00 77 1f cc 2a 80 33 29 00 00 08 ec 00 55 00 00 00 49 22 23 00 00 02 ed c3 29 00 00 03 e4 08 2f 23 00 00 02 b2 10 23 00 00 02 b3 02 23 00 00 02 b4 02 29 00 00 05 b5 00 54 00 54 29 00 00 03 b6 c7 31 29 00 00 08 ba 5b aa 02 00 21 01 00 29 00 00 09 bb 00 28 00 28 08 07 07 04 29 00 00 09 bc 00 36 00 28 08 07 07 04 29 00 00 0c bd 77 ff ff ff ba ab ff ff 16 ff 02 29 00 00 04 a4 c0 4a e0 29 00 00 0a a5 20 12 40 01 00 06 2a 0a 00 29 00 00 0a a6 20 12 40 01 00 06 2a 0a 00 23 00 00 02 d9 22 13 00 00 01 21 23 00 00 02 35 00 23 00 00 02 36 0c 23 00 00 02 3a 07 23 78 00 02 11 00 23 78 00 02 29 00];
		sleep-in = [13 0a 00 01 28 13 78 00 01 10];
		sleep-out = [13 78 00 01 11 13 64 00 01 29];

		display-timings {
			clock-frequency = <0x61a80>;
			hactive = <0x190>;
			vactive = <0x190>;
			hback-porch = <0x16>;
			hfront-porch = <0x16>;
			vback-porch = <0x06>;
			vfront-porch = <0x06>;
			hsync-len = <0x0a>;
			vsync-len = <0x02>;
		};
	};

	mt107_lcd7801: lcd7801@7801 {
		work-mode = <0x00>;
		bpp = <0x18>;
		lane-number = <0x01>;
		need-check-esd = <0x00>;
		esd-timeout = <0x7d0>;
		esd-check-reg = <0x0a>;
		esd-return-code = <0x9c>;
		fps = <0x3c>;
		width-mm = <0x44>;
		height-mm = <0x79>;
		panel-name = "lcd_st7801_oled204_mipi";
		power-on-sequence = <0x21 0x01 0x14 0x32 0x01 0x14 0x32 0x00 0x14 0x32 0x01 0x32>;
		power-off-sequence = <0x32 0x00 0x14 0x21 0x00 0x14>;
		init-data = <0x130a0001 0x11230000 0x2350023 0x253 0x20230000 0x2510013 0x14000129>;
		sleep-in = [13 0a 00 01 28 13 78 00 01 10];
		sleep-out = [13 78 00 01 11 13 32 00 01 29];

		display-timings {
			clock-frequency = <0x4ab50>;
			hactive = <0x170>;
			vactive = <0x1c0>;
			hback-porch = <0x04>;
			hfront-porch = <0x08>;
			vback-porch = <0x04>;
			vfront-porch = <0x08>;
			hsync-len = <0x02>;
			vsync-len = <0x02>;
		};

		oled-backlight {
			default-brightness = <0x4e>;
			max-level = <0xff>;
			brightness-levels = <0x230a0002 0x5100230a 0x25101 0x230a0002 0x5102230a 0x25103 0x230a0002 0x5104230a 0x25105 0x230a0002 0x5106230a 0x25107 0x230a0002 0x5108230a 0x25109 0x230a0002 0x510a230a 0x2510b 0x230a0002 0x510c230a 0x2510d 0x230a0002 0x510e230a 0x2510f 0x230a0002 0x5110230a 0x25111 0x230a0002 0x5112230a 0x25113 0x230a0002 0x5114230a 0x25115 0x230a0002 0x5116230a 0x25117 0x230a0002 0x5118230a 0x25119 0x230a0002 0x511a230a 0x2511b 0x230a0002 0x511c230a 0x2511d 0x230a0002 0x511e230a 0x2511f 0x230a0002 0x5120230a 0x25121 0x230a0002 0x5122230a 0x25123 0x230a0002 0x5124230a 0x25125 0x230a0002 0x5126230a 0x25127 0x230a0002 0x5128230a 0x25129 0x230a0002 0x512a230a 0x2512b 0x230a0002 0x512c230a 0x2512d 0x230a0002 0x512e230a 0x2512f 0x230a0002 0x5130230a 0x25131 0x230a0002 0x5132230a 0x25133 0x230a0002 0x5134230a 0x25135 0x230a0002 0x5136230a 0x25137 0x230a0002 0x5138230a 0x25139 0x230a0002 0x513a230a 0x2513b 0x230a0002 0x513c230a 0x2513d 0x230a0002 0x513e230a 0x2513f 0x230a0002 0x5140230a 0x25141 0x230a0002 0x5142230a 0x25143 0x230a0002 0x5144230a 0x25145 0x230a0002 0x5146230a 0x25147 0x230a0002 0x5148230a 0x25149 0x230a0002 0x514a230a 0x2514b 0x230a0002 0x514c230a 0x2514d 0x230a0002 0x514e230a 0x2514f 0x230a0002 0x5150230a 0x25151 0x230a0002 0x5152230a 0x25153 0x230a0002 0x5154230a 0x25155 0x230a0002 0x5156230a 0x25157 0x230a0002 0x5158230a 0x25159 0x230a0002 0x515a230a 0x2515b 0x230a0002 0x515c230a 0x2515d 0x230a0002 0x515e230a 0x2515f 0x230a0002 0x5160230a 0x25161 0x230a0002 0x5162230a 0x25163 0x230a0002 0x5164230a 0x25165 0x230a0002 0x5166230a 0x25167 0x230a0002 0x5168230a 0x25169 0x230a0002 0x516a230a 0x2516b 0x230a0002 0x516c230a 0x2516d 0x230a0002 0x516e230a 0x2516f 0x230a0002 0x5170230a 0x25171 0x230a0002 0x5172230a 0x25173 0x230a0002 0x5174230a 0x25175 0x230a0002 0x5176230a 0x25177 0x230a0002 0x5178230a 0x25179 0x230a0002 0x517a230a 0x2517b 0x230a0002 0x517c230a 0x2517d 0x230a0002 0x517e230a 0x2517f 0x230a0002 0x5180230a 0x25181 0x230a0002 0x5182230a 0x25183 0x230a0002 0x5184230a 0x25185 0x230a0002 0x5186230a 0x25187 0x230a0002 0x5188230a 0x25189 0x230a0002 0x518a230a 0x2518b 0x230a0002 0x518c230a 0x2518d 0x230a0002 0x518e230a 0x2518f 0x230a0002 0x5190230a 0x25191 0x230a0002 0x5192230a 0x25193 0x230a0002 0x5194230a 0x25195 0x230a0002 0x5196230a 0x25197 0x230a0002 0x5198230a 0x25199 0x230a0002 0x519a230a 0x2519b 0x230a0002 0x519c230a 0x2519d 0x230a0002 0x519e230a 0x2519f 0x230a0002 0x51a0230a 0x251a1 0x230a0002 0x51a2230a 0x251a3 0x230a0002 0x51a4230a 0x251a5 0x230a0002 0x51a6230a 0x251a7 0x230a0002 0x51a8230a 0x251a9 0x230a0002 0x51aa230a 0x251ab 0x230a0002 0x51ac230a 0x251ad 0x230a0002 0x51ae230a 0x251af 0x230a0002 0x51b0230a 0x251b1 0x230a0002 0x51b2230a 0x251b3 0x230a0002 0x51b4230a 0x251b5 0x230a0002 0x51b6230a 0x251b7 0x230a0002 0x51b8230a 0x251b9 0x230a0002 0x51ba230a 0x251bb 0x230a0002 0x51bc230a 0x251bd 0x230a0002 0x51be230a 0x251bf 0x230a0002 0x51c0230a 0x251c1 0x230a0002 0x51c2230a 0x251c3 0x230a0002 0x51c4230a 0x251c5 0x230a0002 0x51c6230a 0x251c7 0x230a0002 0x51c8230a 0x251c9 0x230a0002 0x51ca230a 0x251cb 0x230a0002 0x51cc230a 0x251cd 0x230a0002 0x51ce230a 0x251cf 0x230a0002 0x51d0230a 0x251d1 0x230a0002 0x51d2230a 0x251d3 0x230a0002 0x51d4230a 0x251d5 0x230a0002 0x51d6230a 0x251d7 0x230a0002 0x51d8230a 0x251d9 0x230a0002 0x51da230a 0x251db 0x230a0002 0x51dc230a 0x251dd 0x230a0002 0x51de230a 0x251df 0x230a0002 0x51e0230a 0x251e1 0x230a0002 0x51e2230a 0x251e3 0x230a0002 0x51e4230a 0x251e5 0x230a0002 0x51e6230a 0x251e7 0x230a0002 0x51e8230a 0x251e9 0x230a0002 0x51ea230a 0x251eb 0x230a0002 0x51ec230a 0x251ed 0x230a0002 0x51ee230a 0x251ef 0x230a0002 0x51f0230a 0x251f1 0x230a0002 0x51f2230a 0x251f3 0x230a0002 0x51f4230a 0x251f5 0x230a0002 0x51f6230a 0x251f7 0x230a0002 0x51f8230a 0x251f9 0x230a0002 0x51fa230a 0x251fb 0x230a0002 0x51fc230a 0x251fd 0x230a0002 0x51fe230a 0x251ff>;
		};
	};

	mt107_lcd13613: lcd13613@13613 {
		work-mode = <0x00>;
		bpp = <0x18>;
		lane-number = <0x01>;
		need-check-esd = <0x00>;
		esd-timeout = <0x7d0>;
		esd-check-reg = <0x0a>;
		esd-return-code = <0x9c>;
		fps = <0x3a>;
		width-mm = <0x44>;
		height-mm = <0x79>;
		panel-name = "lcd_ch13613_oled204_mipi";
		power-on-sequence = <0x21 0x01 0x14 0x32 0x01 0x14 0x32 0x00 0x14 0x32 0x01 0x32>;
		power-off-sequence = <0x32 0x00 0x14 0x21 0x00 0x14>;
		init-data = [29 00 00 05 2a 00 10 01 7f 29 00 00 05 2b 00 00 01 bf 23 00 00 02 35 00 23 00 00 02 36 00 23 00 00 02 3a 07 23 00 00 02 64 10 23 00 00 02 67 01 23 00 00 02 68 01 23 00 00 02 f0 50 23 00 00 02 b9 00 23 0a 00 02 51 00 13 64 00 01 11 13 14 00 01 29];
		aod-in = [13 0a 00 01 39];
		aod-out = [13 0a 00 01 38];
		sleep-in = [13 0a 00 01 28 13 78 00 01 10];
		sleep-out = [13 78 00 01 11 13 32 00 01 29];

		display-timings {
			clock-frequency = <0x4ab50>;
			hactive = <0x170>;
			vactive = <0x1c0>;
			hback-porch = <0x08>;
			hfront-porch = <0x0a>;
			vback-porch = <0x0c>;
			vfront-porch = <0x10>;
			hsync-len = <0x02>;
			vsync-len = <0x02>;
		};

		oled-backlight {
			default-brightness = <0x19>;
			max-level = <0xff>;
			brightness-levels = <0x150a0002 0x5100150a 0x25101 0x150a0002 0x5102150a 0x25103 0x150a0002 0x5104150a 0x25105 0x150a0002 0x5106150a 0x25107 0x150a0002 0x5108150a 0x25109 0x150a0002 0x510a150a 0x2510b 0x150a0002 0x510c150a 0x2510d 0x150a0002 0x510e150a 0x2510f 0x150a0002 0x5110150a 0x25111 0x150a0002 0x5112150a 0x25113 0x150a0002 0x5114150a 0x25115 0x150a0002 0x5116150a 0x25117 0x150a0002 0x5118150a 0x25119 0x150a0002 0x511a150a 0x2511b 0x150a0002 0x511c150a 0x2511d 0x150a0002 0x511e150a 0x2511f 0x150a0002 0x5120150a 0x25121 0x150a0002 0x5122150a 0x25123 0x150a0002 0x5124150a 0x25125 0x150a0002 0x5126150a 0x25127 0x150a0002 0x5128150a 0x25129 0x150a0002 0x512a150a 0x2512b 0x150a0002 0x512c150a 0x2512d 0x150a0002 0x512e150a 0x2512f 0x150a0002 0x5130150a 0x25131 0x150a0002 0x5132150a 0x25133 0x150a0002 0x5134150a 0x25135 0x150a0002 0x5136150a 0x25137 0x150a0002 0x5138150a 0x25139 0x150a0002 0x513a150a 0x2513b 0x150a0002 0x513c150a 0x2513d 0x150a0002 0x513e150a 0x2513f 0x150a0002 0x5140150a 0x25141 0x150a0002 0x5142150a 0x25143 0x150a0002 0x5144150a 0x25145 0x150a0002 0x5146150a 0x25147 0x150a0002 0x5148150a 0x25149 0x150a0002 0x514a150a 0x2514b 0x150a0002 0x514c150a 0x2514d 0x150a0002 0x514e150a 0x2514f 0x150a0002 0x5150150a 0x25151 0x150a0002 0x5152150a 0x25153 0x150a0002 0x5154150a 0x25155 0x150a0002 0x5156150a 0x25157 0x150a0002 0x5158150a 0x25159 0x150a0002 0x515a150a 0x2515b 0x150a0002 0x515c150a 0x2515d 0x150a0002 0x515e150a 0x2515f 0x150a0002 0x5160150a 0x25161 0x150a0002 0x5162150a 0x25163 0x150a0002 0x5164150a 0x25165 0x150a0002 0x5166150a 0x25167 0x150a0002 0x5168150a 0x25169 0x150a0002 0x516a150a 0x2516b 0x150a0002 0x516c150a 0x2516d 0x150a0002 0x516e150a 0x2516f 0x150a0002 0x5170150a 0x25171 0x150a0002 0x5172150a 0x25173 0x150a0002 0x5174150a 0x25175 0x150a0002 0x5176150a 0x25177 0x150a0002 0x5178150a 0x25179 0x150a0002 0x517a150a 0x2517b 0x150a0002 0x517c150a 0x2517d 0x150a0002 0x517e150a 0x2517f 0x150a0002 0x5180150a 0x25181 0x150a0002 0x5182150a 0x25183 0x150a0002 0x5184150a 0x25185 0x150a0002 0x5186150a 0x25187 0x150a0002 0x5188150a 0x25189 0x150a0002 0x518a150a 0x2518b 0x150a0002 0x518c150a 0x2518d 0x150a0002 0x518e150a 0x2518f 0x150a0002 0x5190150a 0x25191 0x150a0002 0x5192150a 0x25193 0x150a0002 0x5194150a 0x25195 0x150a0002 0x5196150a 0x25197 0x150a0002 0x5198150a 0x25199 0x150a0002 0x519a150a 0x2519b 0x150a0002 0x519c150a 0x2519d 0x150a0002 0x519e150a 0x2519f 0x150a0002 0x51a0150a 0x251a1 0x150a0002 0x51a2150a 0x251a3 0x150a0002 0x51a4150a 0x251a5 0x150a0002 0x51a6150a 0x251a7 0x150a0002 0x51a8150a 0x251a9 0x150a0002 0x51aa150a 0x251ab 0x150a0002 0x51ac150a 0x251ad 0x150a0002 0x51ae150a 0x251af 0x150a0002 0x51b0150a 0x251b1 0x150a0002 0x51b2150a 0x251b3 0x150a0002 0x51b4150a 0x251b5 0x150a0002 0x51b6150a 0x251b7 0x150a0002 0x51b8150a 0x251b9 0x150a0002 0x51ba150a 0x251bb 0x150a0002 0x51bc150a 0x251bd 0x150a0002 0x51be150a 0x251bf 0x150a0002 0x51c0150a 0x251c1 0x150a0002 0x51c2150a 0x251c3 0x150a0002 0x51c4150a 0x251c5 0x150a0002 0x51c6150a 0x251c7 0x150a0002 0x51c8150a 0x251c9 0x150a0002 0x51ca150a 0x251cb 0x150a0002 0x51cc150a 0x251cd 0x150a0002 0x51ce150a 0x251cf 0x150a0002 0x51d0150a 0x251d1 0x150a0002 0x51d2150a 0x251d3 0x150a0002 0x51d4150a 0x251d5 0x150a0002 0x51d6150a 0x251d7 0x150a0002 0x51d8150a 0x251d9 0x150a0002 0x51da150a 0x251db 0x150a0002 0x51dc150a 0x251dd 0x150a0002 0x51de150a 0x251df 0x150a0002 0x51e0150a 0x251e1 0x150a0002 0x51e2150a 0x251e3 0x150a0002 0x51e4150a 0x251e5 0x150a0002 0x51e6150a 0x251e7 0x150a0002 0x51e8150a 0x251e9 0x150a0002 0x51ea150a 0x251eb 0x150a0002 0x51ec150a 0x251ed 0x150a0002 0x51ee150a 0x251ef 0x150a0002 0x51f0150a 0x251f1 0x150a0002 0x51f2150a 0x251f3 0x150a0002 0x51f4150a 0x251f5 0x150a0002 0x51f6150a 0x251f7 0x150a0002 0x51f8150a 0x251f9 0x150a0002 0x51fa150a 0x251fb 0x150a0002 0x51fc150a 0x251fd 0x150a0002 0x51fe150a 0x251ff>;
		};
	};

	mt107_lcd8601204: lcd8601204@8601204 {
		work-mode = <0x00>;
		bpp = <0x18>;
		lane-number = <0x01>;
		need-check-esd = <0x00>;
		esd-timeout = <0x7d0>;
		esd-check-reg = <0x0a>;
		esd-return-code = <0x9c>;
		fps = <0x3a>;
		width-mm = <0x44>;
		height-mm = <0x79>;
		panel-name = "lcd_sh8601z1_oled204_mipi";
		power-on-sequence = <0x21 0x01 0x14 0x32 0x01 0x14 0x32 0x00 0x14 0x32 0x01 0x32>;
		power-off-sequence = <0x32 0x00 0x14 0x21 0x00 0x14>;
		init-data = [05 0a 00 01 11 39 00 00 05 2a 00 00 01 6f 39 00 00 05 2b 00 00 01 bf 15 00 00 03 44 01 bf 15 00 00 02 3a 77 15 00 00 02 35 00 15 00 00 02 53 20 15 78 00 02 51 00 05 14 00 01 29];
		aod-in = [05 0a 00 01 39];
		aod-out = [05 0a 00 01 38];
		sleep-in = [05 0a 00 01 28 05 78 00 01 10];
		sleep-out = [05 78 00 01 11 05 32 00 01 29];

		display-timings {
			clock-frequency = <0x4ab50>;
			hactive = <0x170>;
			vactive = <0x1c0>;
			hback-porch = <0x08>;
			hfront-porch = <0x0a>;
			vback-porch = <0x0c>;
			vfront-porch = <0x10>;
			hsync-len = <0x02>;
			vsync-len = <0x02>;
		};

		oled-backlight {
			default-brightness = <0x19>;
			max-level = <0xff>;
			brightness-levels = <0x150a0002 0x5100150a 0x25101 0x150a0002 0x5102150a 0x25103 0x150a0002 0x5104150a 0x25105 0x150a0002 0x5106150a 0x25107 0x150a0002 0x5108150a 0x25109 0x150a0002 0x510a150a 0x2510b 0x150a0002 0x510c150a 0x2510d 0x150a0002 0x510e150a 0x2510f 0x150a0002 0x5110150a 0x25111 0x150a0002 0x5112150a 0x25113 0x150a0002 0x5114150a 0x25115 0x150a0002 0x5116150a 0x25117 0x150a0002 0x5118150a 0x25119 0x150a0002 0x511a150a 0x2511b 0x150a0002 0x511c150a 0x2511d 0x150a0002 0x511e150a 0x2511f 0x150a0002 0x5120150a 0x25121 0x150a0002 0x5122150a 0x25123 0x150a0002 0x5124150a 0x25125 0x150a0002 0x5126150a 0x25127 0x150a0002 0x5128150a 0x25129 0x150a0002 0x512a150a 0x2512b 0x150a0002 0x512c150a 0x2512d 0x150a0002 0x512e150a 0x2512f 0x150a0002 0x5130150a 0x25131 0x150a0002 0x5132150a 0x25133 0x150a0002 0x5134150a 0x25135 0x150a0002 0x5136150a 0x25137 0x150a0002 0x5138150a 0x25139 0x150a0002 0x513a150a 0x2513b 0x150a0002 0x513c150a 0x2513d 0x150a0002 0x513e150a 0x2513f 0x150a0002 0x5140150a 0x25141 0x150a0002 0x5142150a 0x25143 0x150a0002 0x5144150a 0x25145 0x150a0002 0x5146150a 0x25147 0x150a0002 0x5148150a 0x25149 0x150a0002 0x514a150a 0x2514b 0x150a0002 0x514c150a 0x2514d 0x150a0002 0x514e150a 0x2514f 0x150a0002 0x5150150a 0x25151 0x150a0002 0x5152150a 0x25153 0x150a0002 0x5154150a 0x25155 0x150a0002 0x5156150a 0x25157 0x150a0002 0x5158150a 0x25159 0x150a0002 0x515a150a 0x2515b 0x150a0002 0x515c150a 0x2515d 0x150a0002 0x515e150a 0x2515f 0x150a0002 0x5160150a 0x25161 0x150a0002 0x5162150a 0x25163 0x150a0002 0x5164150a 0x25165 0x150a0002 0x5166150a 0x25167 0x150a0002 0x5168150a 0x25169 0x150a0002 0x516a150a 0x2516b 0x150a0002 0x516c150a 0x2516d 0x150a0002 0x516e150a 0x2516f 0x150a0002 0x5170150a 0x25171 0x150a0002 0x5172150a 0x25173 0x150a0002 0x5174150a 0x25175 0x150a0002 0x5176150a 0x25177 0x150a0002 0x5178150a 0x25179 0x150a0002 0x517a150a 0x2517b 0x150a0002 0x517c150a 0x2517d 0x150a0002 0x517e150a 0x2517f 0x150a0002 0x5180150a 0x25181 0x150a0002 0x5182150a 0x25183 0x150a0002 0x5184150a 0x25185 0x150a0002 0x5186150a 0x25187 0x150a0002 0x5188150a 0x25189 0x150a0002 0x518a150a 0x2518b 0x150a0002 0x518c150a 0x2518d 0x150a0002 0x518e150a 0x2518f 0x150a0002 0x5190150a 0x25191 0x150a0002 0x5192150a 0x25193 0x150a0002 0x5194150a 0x25195 0x150a0002 0x5196150a 0x25197 0x150a0002 0x5198150a 0x25199 0x150a0002 0x519a150a 0x2519b 0x150a0002 0x519c150a 0x2519d 0x150a0002 0x519e150a 0x2519f 0x150a0002 0x51a0150a 0x251a1 0x150a0002 0x51a2150a 0x251a3 0x150a0002 0x51a4150a 0x251a5 0x150a0002 0x51a6150a 0x251a7 0x150a0002 0x51a8150a 0x251a9 0x150a0002 0x51aa150a 0x251ab 0x150a0002 0x51ac150a 0x251ad 0x150a0002 0x51ae150a 0x251af 0x150a0002 0x51b0150a 0x251b1 0x150a0002 0x51b2150a 0x251b3 0x150a0002 0x51b4150a 0x251b5 0x150a0002 0x51b6150a 0x251b7 0x150a0002 0x51b8150a 0x251b9 0x150a0002 0x51ba150a 0x251bb 0x150a0002 0x51bc150a 0x251bd 0x150a0002 0x51be150a 0x251bf 0x150a0002 0x51c0150a 0x251c1 0x150a0002 0x51c2150a 0x251c3 0x150a0002 0x51c4150a 0x251c5 0x150a0002 0x51c6150a 0x251c7 0x150a0002 0x51c8150a 0x251c9 0x150a0002 0x51ca150a 0x251cb 0x150a0002 0x51cc150a 0x251cd 0x150a0002 0x51ce150a 0x251cf 0x150a0002 0x51d0150a 0x251d1 0x150a0002 0x51d2150a 0x251d3 0x150a0002 0x51d4150a 0x251d5 0x150a0002 0x51d6150a 0x251d7 0x150a0002 0x51d8150a 0x251d9 0x150a0002 0x51da150a 0x251db 0x150a0002 0x51dc150a 0x251dd 0x150a0002 0x51de150a 0x251df 0x150a0002 0x51e0150a 0x251e1 0x150a0002 0x51e2150a 0x251e3 0x150a0002 0x51e4150a 0x251e5 0x150a0002 0x51e6150a 0x251e7 0x150a0002 0x51e8150a 0x251e9 0x150a0002 0x51ea150a 0x251eb 0x150a0002 0x51ec150a 0x251ed 0x150a0002 0x51ee150a 0x251ef 0x150a0002 0x51f0150a 0x251f1 0x150a0002 0x51f2150a 0x251f3 0x150a0002 0x51f4150a 0x251f5 0x150a0002 0x51f6150a 0x251f7 0x150a0002 0x51f8150a 0x251f9 0x150a0002 0x51fa150a 0x251fb 0x150a0002 0x51fc150a 0x251fd 0x150a0002 0x51fe150a 0x251ff>;
		};
	};

	mt107_lcd86011952: lcd86011952@86011952 {
		work-mode = <0x00>;
		bpp = <0x18>;
		lane-number = <0x01>;
		need-check-esd = <0x00>;
		esd-timeout = <0x7d0>;
		esd-check-reg = <0x0a>;
		esd-return-code = <0x9c>;
		fps = <0x3c>;
		width-mm = <0x44>;
		height-mm = <0x79>;
		panel-name = "lcd_sh8601_oled1952_mipi";
		power-on-sequence = <0x21 0x01 0x14 0x32 0x01 0x14 0x32 0x00 0x14 0x32 0x01 0x32>;
		power-off-sequence = <0x32 0x00 0x14 0x21 0x00 0x14>;
		init-data = [23 00 00 03 c0 5a 5a 23 00 00 03 c1 5a 5a 23 00 00 02 e4 01 23 00 00 02 b0 2c 29 00 00 1f be fb 01 fb 01 fb 01 fb 01 fb 01 fb 01 fb 01 fb 01 fb 01 24 00 40 00 00 00 6e 00 fb 01 fb 01 13 1a 00 01 11 29 00 00 05 2a 00 00 01 9b 29 00 00 05 2b 00 00 01 f5 23 00 00 03 c0 5a 5a 23 00 00 03 c1 5a 5a 23 00 00 02 b0 02 29 00 00 05 b1 f6 01 9c 01 23 00 00 02 b0 02 23 00 00 03 d3 9c 01 23 00 00 03 44 00 00 23 00 00 02 3a 77 23 00 00 02 35 00 23 00 00 02 53 20 23 78 00 02 51 00 13 14 00 01 29];
		aod-in = [13 0a 00 01 39];
		aod-out = [13 0a 00 01 38];
		sleep-in = [13 0a 00 01 28 13 78 00 01 10];
		sleep-out = [13 78 00 01 11 13 32 00 01 29];

		display-timings {
			clock-frequency = <0x704e0>;
			hactive = <0x19c>;
			vactive = <0x1f6>;
			hback-porch = <0x12>;
			hfront-porch = <0x30>;
			hsync-len = <0x02>;
			vfront-porch = <0x1e>;
			vback-porch = <0x18>;
			vsync-len = <0x02>;
		};

		oled-backlight {
			default-brightness = <0x19>;
			max-level = <0xff>;
			brightness-levels = <0x230a0002 0x5100230a 0x25101 0x230a0002 0x5102230a 0x25103 0x230a0002 0x5104230a 0x25105 0x230a0002 0x5106230a 0x25107 0x230a0002 0x5108230a 0x25109 0x230a0002 0x510a230a 0x2510b 0x230a0002 0x510c230a 0x2510d 0x230a0002 0x510e230a 0x2510f 0x230a0002 0x5110230a 0x25111 0x230a0002 0x5112230a 0x25113 0x230a0002 0x5114230a 0x25115 0x230a0002 0x5116230a 0x25117 0x230a0002 0x5118230a 0x25119 0x230a0002 0x511a230a 0x2511b 0x230a0002 0x511c230a 0x2511d 0x230a0002 0x511e230a 0x2511f 0x230a0002 0x5120230a 0x25121 0x230a0002 0x5122230a 0x25123 0x230a0002 0x5124230a 0x25125 0x230a0002 0x5126230a 0x25127 0x230a0002 0x5128230a 0x25129 0x230a0002 0x512a230a 0x2512b 0x230a0002 0x512c230a 0x2512d 0x230a0002 0x512e230a 0x2512f 0x230a0002 0x5130230a 0x25131 0x230a0002 0x5132230a 0x25133 0x230a0002 0x5134230a 0x25135 0x230a0002 0x5136230a 0x25137 0x230a0002 0x5138230a 0x25139 0x230a0002 0x513a230a 0x2513b 0x230a0002 0x513c230a 0x2513d 0x230a0002 0x513e230a 0x2513f 0x230a0002 0x5140230a 0x25141 0x230a0002 0x5142230a 0x25143 0x230a0002 0x5144230a 0x25145 0x230a0002 0x5146230a 0x25147 0x230a0002 0x5148230a 0x25149 0x230a0002 0x514a230a 0x2514b 0x230a0002 0x514c230a 0x2514d 0x230a0002 0x514e230a 0x2514f 0x230a0002 0x5150230a 0x25151 0x230a0002 0x5152230a 0x25153 0x230a0002 0x5154230a 0x25155 0x230a0002 0x5156230a 0x25157 0x230a0002 0x5158230a 0x25159 0x230a0002 0x515a230a 0x2515b 0x230a0002 0x515c230a 0x2515d 0x230a0002 0x515e230a 0x2515f 0x230a0002 0x5160230a 0x25161 0x230a0002 0x5162230a 0x25163 0x230a0002 0x5164230a 0x25165 0x230a0002 0x5166230a 0x25167 0x230a0002 0x5168230a 0x25169 0x230a0002 0x516a230a 0x2516b 0x230a0002 0x516c230a 0x2516d 0x230a0002 0x516e230a 0x2516f 0x230a0002 0x5170230a 0x25171 0x230a0002 0x5172230a 0x25173 0x230a0002 0x5174230a 0x25175 0x230a0002 0x5176230a 0x25177 0x230a0002 0x5178230a 0x25179 0x230a0002 0x517a230a 0x2517b 0x230a0002 0x517c230a 0x2517d 0x230a0002 0x517e230a 0x2517f 0x230a0002 0x5180230a 0x25181 0x230a0002 0x5182230a 0x25183 0x230a0002 0x5184230a 0x25185 0x230a0002 0x5186230a 0x25187 0x230a0002 0x5188230a 0x25189 0x230a0002 0x518a230a 0x2518b 0x230a0002 0x518c230a 0x2518d 0x230a0002 0x518e230a 0x2518f 0x230a0002 0x5190230a 0x25191 0x230a0002 0x5192230a 0x25193 0x230a0002 0x5194230a 0x25195 0x230a0002 0x5196230a 0x25197 0x230a0002 0x5198230a 0x25199 0x230a0002 0x519a230a 0x2519b 0x230a0002 0x519c230a 0x2519d 0x230a0002 0x519e230a 0x2519f 0x230a0002 0x51a0230a 0x251a1 0x230a0002 0x51a2230a 0x251a3 0x230a0002 0x51a4230a 0x251a5 0x230a0002 0x51a6230a 0x251a7 0x230a0002 0x51a8230a 0x251a9 0x230a0002 0x51aa230a 0x251ab 0x230a0002 0x51ac230a 0x251ad 0x230a0002 0x51ae230a 0x251af 0x230a0002 0x51b0230a 0x251b1 0x230a0002 0x51b2230a 0x251b3 0x230a0002 0x51b4230a 0x251b5 0x230a0002 0x51b6230a 0x251b7 0x230a0002 0x51b8230a 0x251b9 0x230a0002 0x51ba230a 0x251bb 0x230a0002 0x51bc230a 0x251bd 0x230a0002 0x51be230a 0x251bf 0x230a0002 0x51c0230a 0x251c1 0x230a0002 0x51c2230a 0x251c3 0x230a0002 0x51c4230a 0x251c5 0x230a0002 0x51c6230a 0x251c7 0x230a0002 0x51c8230a 0x251c9 0x230a0002 0x51ca230a 0x251cb 0x230a0002 0x51cc230a 0x251cd 0x230a0002 0x51ce230a 0x251cf 0x230a0002 0x51d0230a 0x251d1 0x230a0002 0x51d2230a 0x251d3 0x230a0002 0x51d4230a 0x251d5 0x230a0002 0x51d6230a 0x251d7 0x230a0002 0x51d8230a 0x251d9 0x230a0002 0x51da230a 0x251db 0x230a0002 0x51dc230a 0x251dd 0x230a0002 0x51de230a 0x251df 0x230a0002 0x51e0230a 0x251e1 0x230a0002 0x51e2230a 0x251e3 0x230a0002 0x51e4230a 0x251e5 0x230a0002 0x51e6230a 0x251e7 0x230a0002 0x51e8230a 0x251e9 0x230a0002 0x51ea230a 0x251eb 0x230a0002 0x51ec230a 0x251ed 0x230a0002 0x51ee230a 0x251ef 0x230a0002 0x51f0230a 0x251f1 0x230a0002 0x51f2230a 0x251f3 0x230a0002 0x51f4230a 0x251f5 0x230a0002 0x51f6230a 0x251f7 0x230a0002 0x51f8230a 0x251f9 0x230a0002 0x51fa230a 0x251fb 0x230a0002 0x51fc230a 0x251fd 0x230a0002 0x51fe230a 0x251ff>;
		};
	};

	mt107_lcd5300178: lcd5300178@5300178 {
		work-mode = <0x00>;
		bpp = <0x18>;
		lane-number = <0x01>;
		need-check-esd = <0x00>;
		esd-timeout = <0x7d0>;
		esd-check-reg = <0x0a>;
		esd-return-code = <0x9c>;
		fps = <0x3c>;
		width-mm = <0x44>;
		height-mm = <0x79>;
		panel-name = "lcd_co5300_oled178_mipi";
		power-on-sequence = <0x21 0x01 0x14 0x32 0x01 0x14 0x32 0x00 0x14 0x32 0x01 0x32>;
		power-off-sequence = <0x32 0x00 0x14 0x21 0x00 0x14>;
		init-data = [23 00 00 02 fe 20 23 00 00 02 f4 5a 23 00 00 02 f5 59 23 00 00 02 fe 40 23 00 00 02 a0 fc 23 00 00 02 fe 00 23 00 00 02 35 00 23 00 00 02 3a 77 23 00 00 02 53 20 23 00 00 02 51 00 23 00 00 02 63 ff 29 00 00 05 2a 00 10 01 7f 29 00 00 05 2b 00 00 01 bf 13 78 00 01 11 13 14 00 01 29];
		aod-in = [23 00 00 02 fe 00 13 0a 00 01 39];
		aod-out = [23 00 00 02 fe 00 13 0a 00 01 38];
		sleep-in = [13 0a 00 01 28 13 78 00 01 10];
		sleep-out = [13 78 00 01 11 13 32 00 01 29];

		display-timings {
			clock-frequency = <0x518b0>;
			hactive = <0x170>;
			vactive = <0x1c0>;
			hback-porch = <0x18>;
			hfront-porch = <0x10>;
			hsync-len = <0x04>;
			vfront-porch = <0x09>;
			vback-porch = <0x08>;
			vsync-len = <0x02>;
		};

		oled-backlight {
			default-brightness = <0x78>;
			max-level = <0xff>;
			brightness-levels = <0x230a0002 0x5100230a 0x25101 0x230a0002 0x5102230a 0x25103 0x230a0002 0x5104230a 0x25105 0x230a0002 0x5106230a 0x25107 0x230a0002 0x5108230a 0x25109 0x230a0002 0x510a230a 0x2510b 0x230a0002 0x510c230a 0x2510d 0x230a0002 0x510e230a 0x2510f 0x230a0002 0x5110230a 0x25111 0x230a0002 0x5112230a 0x25113 0x230a0002 0x5114230a 0x25115 0x230a0002 0x5116230a 0x25117 0x230a0002 0x5118230a 0x25119 0x230a0002 0x511a230a 0x2511b 0x230a0002 0x511c230a 0x2511d 0x230a0002 0x511e230a 0x2511f 0x230a0002 0x5120230a 0x25121 0x230a0002 0x5122230a 0x25123 0x230a0002 0x5124230a 0x25125 0x230a0002 0x5126230a 0x25127 0x230a0002 0x5128230a 0x25129 0x230a0002 0x512a230a 0x2512b 0x230a0002 0x512c230a 0x2512d 0x230a0002 0x512e230a 0x2512f 0x230a0002 0x5130230a 0x25131 0x230a0002 0x5132230a 0x25133 0x230a0002 0x5134230a 0x25135 0x230a0002 0x5136230a 0x25137 0x230a0002 0x5138230a 0x25139 0x230a0002 0x513a230a 0x2513b 0x230a0002 0x513c230a 0x2513d 0x230a0002 0x513e230a 0x2513f 0x230a0002 0x5140230a 0x25141 0x230a0002 0x5142230a 0x25143 0x230a0002 0x5144230a 0x25145 0x230a0002 0x5146230a 0x25147 0x230a0002 0x5148230a 0x25149 0x230a0002 0x514a230a 0x2514b 0x230a0002 0x514c230a 0x2514d 0x230a0002 0x514e230a 0x2514f 0x230a0002 0x5150230a 0x25151 0x230a0002 0x5152230a 0x25153 0x230a0002 0x5154230a 0x25155 0x230a0002 0x5156230a 0x25157 0x230a0002 0x5158230a 0x25159 0x230a0002 0x515a230a 0x2515b 0x230a0002 0x515c230a 0x2515d 0x230a0002 0x515e230a 0x2515f 0x230a0002 0x5160230a 0x25161 0x230a0002 0x5162230a 0x25163 0x230a0002 0x5164230a 0x25165 0x230a0002 0x5166230a 0x25167 0x230a0002 0x5168230a 0x25169 0x230a0002 0x516a230a 0x2516b 0x230a0002 0x516c230a 0x2516d 0x230a0002 0x516e230a 0x2516f 0x230a0002 0x5170230a 0x25171 0x230a0002 0x5172230a 0x25173 0x230a0002 0x5174230a 0x25175 0x230a0002 0x5176230a 0x25177 0x230a0002 0x5178230a 0x25179 0x230a0002 0x517a230a 0x2517b 0x230a0002 0x517c230a 0x2517d 0x230a0002 0x517e230a 0x2517f 0x230a0002 0x5180230a 0x25181 0x230a0002 0x5182230a 0x25183 0x230a0002 0x5184230a 0x25185 0x230a0002 0x5186230a 0x25187 0x230a0002 0x5188230a 0x25189 0x230a0002 0x518a230a 0x2518b 0x230a0002 0x518c230a 0x2518d 0x230a0002 0x518e230a 0x2518f 0x230a0002 0x5190230a 0x25191 0x230a0002 0x5192230a 0x25193 0x230a0002 0x5194230a 0x25195 0x230a0002 0x5196230a 0x25197 0x230a0002 0x5198230a 0x25199 0x230a0002 0x519a230a 0x2519b 0x230a0002 0x519c230a 0x2519d 0x230a0002 0x519e230a 0x2519f 0x230a0002 0x51a0230a 0x251a1 0x230a0002 0x51a2230a 0x251a3 0x230a0002 0x51a4230a 0x251a5 0x230a0002 0x51a6230a 0x251a7 0x230a0002 0x51a8230a 0x251a9 0x230a0002 0x51aa230a 0x251ab 0x230a0002 0x51ac230a 0x251ad 0x230a0002 0x51ae230a 0x251af 0x230a0002 0x51b0230a 0x251b1 0x230a0002 0x51b2230a 0x251b3 0x230a0002 0x51b4230a 0x251b5 0x230a0002 0x51b6230a 0x251b7 0x230a0002 0x51b8230a 0x251b9 0x230a0002 0x51ba230a 0x251bb 0x230a0002 0x51bc230a 0x251bd 0x230a0002 0x51be230a 0x251bf 0x230a0002 0x51c0230a 0x251c1 0x230a0002 0x51c2230a 0x251c3 0x230a0002 0x51c4230a 0x251c5 0x230a0002 0x51c6230a 0x251c7 0x230a0002 0x51c8230a 0x251c9 0x230a0002 0x51ca230a 0x251cb 0x230a0002 0x51cc230a 0x251cd 0x230a0002 0x51ce230a 0x251cf 0x230a0002 0x51d0230a 0x251d1 0x230a0002 0x51d2230a 0x251d3 0x230a0002 0x51d4230a 0x251d5 0x230a0002 0x51d6230a 0x251d7 0x230a0002 0x51d8230a 0x251d9 0x230a0002 0x51da230a 0x251db 0x230a0002 0x51dc230a 0x251dd 0x230a0002 0x51de230a 0x251df 0x230a0002 0x51e0230a 0x251e1 0x230a0002 0x51e2230a 0x251e3 0x230a0002 0x51e4230a 0x251e5 0x230a0002 0x51e6230a 0x251e7 0x230a0002 0x51e8230a 0x251e9 0x230a0002 0x51ea230a 0x251eb 0x230a0002 0x51ec230a 0x251ed 0x230a0002 0x51ee230a 0x251ef 0x230a0002 0x51f0230a 0x251f1 0x230a0002 0x51f2230a 0x251f3 0x230a0002 0x51f4230a 0x251f5 0x230a0002 0x51f6230a 0x251f7 0x230a0002 0x51f8230a 0x251f9 0x230a0002 0x51fa230a 0x251fb 0x230a0002 0x51fc230a 0x251fd 0x230a0002 0x51fe230a 0x251ff>;
		};
	};

	mt107_lcd53001952: lcd53001952@53001952 {
		work-mode = <0x00>;
		bpp = <0x18>;
		lane-number = <0x01>;
		need-check-esd = <0x00>;
		esd-timeout = <0x7d0>;
		esd-check-reg = <0x0a>;
		esd-return-code = <0x9c>;
		fps = <0x3c>;
		width-mm = <0x44>;
		height-mm = <0x79>;
		panel-name = "lcd_co5300_oled1952_mipi";
		power-on-sequence = <0x21 0x01 0x14 0x32 0x01 0x14 0x32 0x00 0x14 0x32 0x01 0x32>;
		power-off-sequence = <0x32 0x00 0x14 0x21 0x00 0x14>;
		init-data = <0x23000002 0xfe202300 0x2f45a 0x23000002 0xf5592300 0x2fed0 0x23000002 0x2a802300 0x22b02 0x23000002 0xfe902300 0x24e1f 0x23000002 0xfe002300 0x23500 0x23000002 0x3a772300 0x25320 0x23000002 0x51002300 0x263ff 0x29000005 0x2a002b01 0xc6290000 0x52b0000 0x1f51378 0x11113 0x14000129>;
		aod-in = [23 00 00 02 fe 00 13 0a 00 01 39];
		aod-out = [23 00 00 02 fe 00 13 0a 00 01 38];
		sleep-in = [13 0a 00 01 28 13 78 00 01 10];
		sleep-out = [13 78 00 01 11 13 32 00 01 29];

		display-timings {
			clock-frequency = <0x63da8>;
			hactive = <0x19c>;
			vactive = <0x1f6>;
			hback-porch = <0x18>;
			hfront-porch = <0x10>;
			hsync-len = <0x04>;
			vfront-porch = <0x09>;
			vback-porch = <0x08>;
			vsync-len = <0x01>;
		};

		oled-backlight {
			default-brightness = <0x78>;
			max-level = <0xff>;
			brightness-levels = <0x230a0002 0x5100230a 0x25101 0x230a0002 0x5102230a 0x25103 0x230a0002 0x5104230a 0x25105 0x230a0002 0x5106230a 0x25107 0x230a0002 0x5108230a 0x25109 0x230a0002 0x510a230a 0x2510b 0x230a0002 0x510c230a 0x2510d 0x230a0002 0x510e230a 0x2510f 0x230a0002 0x5110230a 0x25111 0x230a0002 0x5112230a 0x25113 0x230a0002 0x5114230a 0x25115 0x230a0002 0x5116230a 0x25117 0x230a0002 0x5118230a 0x25119 0x230a0002 0x511a230a 0x2511b 0x230a0002 0x511c230a 0x2511d 0x230a0002 0x511e230a 0x2511f 0x230a0002 0x5120230a 0x25121 0x230a0002 0x5122230a 0x25123 0x230a0002 0x5124230a 0x25125 0x230a0002 0x5126230a 0x25127 0x230a0002 0x5128230a 0x25129 0x230a0002 0x512a230a 0x2512b 0x230a0002 0x512c230a 0x2512d 0x230a0002 0x512e230a 0x2512f 0x230a0002 0x5130230a 0x25131 0x230a0002 0x5132230a 0x25133 0x230a0002 0x5134230a 0x25135 0x230a0002 0x5136230a 0x25137 0x230a0002 0x5138230a 0x25139 0x230a0002 0x513a230a 0x2513b 0x230a0002 0x513c230a 0x2513d 0x230a0002 0x513e230a 0x2513f 0x230a0002 0x5140230a 0x25141 0x230a0002 0x5142230a 0x25143 0x230a0002 0x5144230a 0x25145 0x230a0002 0x5146230a 0x25147 0x230a0002 0x5148230a 0x25149 0x230a0002 0x514a230a 0x2514b 0x230a0002 0x514c230a 0x2514d 0x230a0002 0x514e230a 0x2514f 0x230a0002 0x5150230a 0x25151 0x230a0002 0x5152230a 0x25153 0x230a0002 0x5154230a 0x25155 0x230a0002 0x5156230a 0x25157 0x230a0002 0x5158230a 0x25159 0x230a0002 0x515a230a 0x2515b 0x230a0002 0x515c230a 0x2515d 0x230a0002 0x515e230a 0x2515f 0x230a0002 0x5160230a 0x25161 0x230a0002 0x5162230a 0x25163 0x230a0002 0x5164230a 0x25165 0x230a0002 0x5166230a 0x25167 0x230a0002 0x5168230a 0x25169 0x230a0002 0x516a230a 0x2516b 0x230a0002 0x516c230a 0x2516d 0x230a0002 0x516e230a 0x2516f 0x230a0002 0x5170230a 0x25171 0x230a0002 0x5172230a 0x25173 0x230a0002 0x5174230a 0x25175 0x230a0002 0x5176230a 0x25177 0x230a0002 0x5178230a 0x25179 0x230a0002 0x517a230a 0x2517b 0x230a0002 0x517c230a 0x2517d 0x230a0002 0x517e230a 0x2517f 0x230a0002 0x5180230a 0x25181 0x230a0002 0x5182230a 0x25183 0x230a0002 0x5184230a 0x25185 0x230a0002 0x5186230a 0x25187 0x230a0002 0x5188230a 0x25189 0x230a0002 0x518a230a 0x2518b 0x230a0002 0x518c230a 0x2518d 0x230a0002 0x518e230a 0x2518f 0x230a0002 0x5190230a 0x25191 0x230a0002 0x5192230a 0x25193 0x230a0002 0x5194230a 0x25195 0x230a0002 0x5196230a 0x25197 0x230a0002 0x5198230a 0x25199 0x230a0002 0x519a230a 0x2519b 0x230a0002 0x519c230a 0x2519d 0x230a0002 0x519e230a 0x2519f 0x230a0002 0x51a0230a 0x251a1 0x230a0002 0x51a2230a 0x251a3 0x230a0002 0x51a4230a 0x251a5 0x230a0002 0x51a6230a 0x251a7 0x230a0002 0x51a8230a 0x251a9 0x230a0002 0x51aa230a 0x251ab 0x230a0002 0x51ac230a 0x251ad 0x230a0002 0x51ae230a 0x251af 0x230a0002 0x51b0230a 0x251b1 0x230a0002 0x51b2230a 0x251b3 0x230a0002 0x51b4230a 0x251b5 0x230a0002 0x51b6230a 0x251b7 0x230a0002 0x51b8230a 0x251b9 0x230a0002 0x51ba230a 0x251bb 0x230a0002 0x51bc230a 0x251bd 0x230a0002 0x51be230a 0x251bf 0x230a0002 0x51c0230a 0x251c1 0x230a0002 0x51c2230a 0x251c3 0x230a0002 0x51c4230a 0x251c5 0x230a0002 0x51c6230a 0x251c7 0x230a0002 0x51c8230a 0x251c9 0x230a0002 0x51ca230a 0x251cb 0x230a0002 0x51cc230a 0x251cd 0x230a0002 0x51ce230a 0x251cf 0x230a0002 0x51d0230a 0x251d1 0x230a0002 0x51d2230a 0x251d3 0x230a0002 0x51d4230a 0x251d5 0x230a0002 0x51d6230a 0x251d7 0x230a0002 0x51d8230a 0x251d9 0x230a0002 0x51da230a 0x251db 0x230a0002 0x51dc230a 0x251dd 0x230a0002 0x51de230a 0x251df 0x230a0002 0x51e0230a 0x251e1 0x230a0002 0x51e2230a 0x251e3 0x230a0002 0x51e4230a 0x251e5 0x230a0002 0x51e6230a 0x251e7 0x230a0002 0x51e8230a 0x251e9 0x230a0002 0x51ea230a 0x251eb 0x230a0002 0x51ec230a 0x251ed 0x230a0002 0x51ee230a 0x251ef 0x230a0002 0x51f0230a 0x251f1 0x230a0002 0x51f2230a 0x251f3 0x230a0002 0x51f4230a 0x251f5 0x230a0002 0x51f6230a 0x251f7 0x230a0002 0x51f8230a 0x251f9 0x230a0002 0x51fa230a 0x251fb 0x230a0002 0x51fc230a 0x251fd 0x230a0002 0x51fe230a 0x251ff>;
		};
	};

	mt107_lcd5300204: lcd5300204@5300204 {
		work-mode = <0x00>;
		bpp = <0x18>;
		lane-number = <0x01>;
		need-check-esd = <0x00>;
		esd-timeout = <0x7d0>;
		esd-check-reg = <0x0a>;
		esd-return-code = <0x9c>;
		fps = <0x3c>;
		width-mm = <0x44>;
		height-mm = <0x79>;
		panel-name = "lcd_co5300_oled204_mipi";
		power-on-sequence = <0x21 0x01 0x14 0x32 0x01 0x14 0x32 0x00 0x14 0x32 0x01 0x32>;
		power-off-sequence = <0x32 0x00 0x14 0x21 0x00 0x14>;
		init-data = <0x23000002 0xfe002300 0x23500 0x23000002 0x3a772300 0x25320 0x23000002 0x51002300 0x263ff 0x29000005 0x2a001001 0x7f290000 0x52b0000 0x1bf1378 0x11113 0x14000129>;
		aod-in = [23 00 00 02 fe 00 13 0a 00 01 39];
		aod-out = [23 00 00 02 fe 00 13 0a 00 01 38];
		sleep-in = [13 0a 00 01 28 13 78 00 01 10];
		sleep-out = [13 78 00 01 11 13 32 00 01 29];

		display-timings {
			clock-frequency = <0x518b0>;
			hactive = <0x170>;
			vactive = <0x1c0>;
			hback-porch = <0x18>;
			hfront-porch = <0x10>;
			hsync-len = <0x04>;
			vfront-porch = <0x09>;
			vback-porch = <0x08>;
			vsync-len = <0x02>;
		};

		oled-backlight {
			default-brightness = <0x78>;
			max-level = <0xff>;
			brightness-levels = <0x230a0002 0x5100230a 0x25101 0x230a0002 0x5102230a 0x25103 0x230a0002 0x5104230a 0x25105 0x230a0002 0x5106230a 0x25107 0x230a0002 0x5108230a 0x25109 0x230a0002 0x510a230a 0x2510b 0x230a0002 0x510c230a 0x2510d 0x230a0002 0x510e230a 0x2510f 0x230a0002 0x5110230a 0x25111 0x230a0002 0x5112230a 0x25113 0x230a0002 0x5114230a 0x25115 0x230a0002 0x5116230a 0x25117 0x230a0002 0x5118230a 0x25119 0x230a0002 0x511a230a 0x2511b 0x230a0002 0x511c230a 0x2511d 0x230a0002 0x511e230a 0x2511f 0x230a0002 0x5120230a 0x25121 0x230a0002 0x5122230a 0x25123 0x230a0002 0x5124230a 0x25125 0x230a0002 0x5126230a 0x25127 0x230a0002 0x5128230a 0x25129 0x230a0002 0x512a230a 0x2512b 0x230a0002 0x512c230a 0x2512d 0x230a0002 0x512e230a 0x2512f 0x230a0002 0x5130230a 0x25131 0x230a0002 0x5132230a 0x25133 0x230a0002 0x5134230a 0x25135 0x230a0002 0x5136230a 0x25137 0x230a0002 0x5138230a 0x25139 0x230a0002 0x513a230a 0x2513b 0x230a0002 0x513c230a 0x2513d 0x230a0002 0x513e230a 0x2513f 0x230a0002 0x5140230a 0x25141 0x230a0002 0x5142230a 0x25143 0x230a0002 0x5144230a 0x25145 0x230a0002 0x5146230a 0x25147 0x230a0002 0x5148230a 0x25149 0x230a0002 0x514a230a 0x2514b 0x230a0002 0x514c230a 0x2514d 0x230a0002 0x514e230a 0x2514f 0x230a0002 0x5150230a 0x25151 0x230a0002 0x5152230a 0x25153 0x230a0002 0x5154230a 0x25155 0x230a0002 0x5156230a 0x25157 0x230a0002 0x5158230a 0x25159 0x230a0002 0x515a230a 0x2515b 0x230a0002 0x515c230a 0x2515d 0x230a0002 0x515e230a 0x2515f 0x230a0002 0x5160230a 0x25161 0x230a0002 0x5162230a 0x25163 0x230a0002 0x5164230a 0x25165 0x230a0002 0x5166230a 0x25167 0x230a0002 0x5168230a 0x25169 0x230a0002 0x516a230a 0x2516b 0x230a0002 0x516c230a 0x2516d 0x230a0002 0x516e230a 0x2516f 0x230a0002 0x5170230a 0x25171 0x230a0002 0x5172230a 0x25173 0x230a0002 0x5174230a 0x25175 0x230a0002 0x5176230a 0x25177 0x230a0002 0x5178230a 0x25179 0x230a0002 0x517a230a 0x2517b 0x230a0002 0x517c230a 0x2517d 0x230a0002 0x517e230a 0x2517f 0x230a0002 0x5180230a 0x25181 0x230a0002 0x5182230a 0x25183 0x230a0002 0x5184230a 0x25185 0x230a0002 0x5186230a 0x25187 0x230a0002 0x5188230a 0x25189 0x230a0002 0x518a230a 0x2518b 0x230a0002 0x518c230a 0x2518d 0x230a0002 0x518e230a 0x2518f 0x230a0002 0x5190230a 0x25191 0x230a0002 0x5192230a 0x25193 0x230a0002 0x5194230a 0x25195 0x230a0002 0x5196230a 0x25197 0x230a0002 0x5198230a 0x25199 0x230a0002 0x519a230a 0x2519b 0x230a0002 0x519c230a 0x2519d 0x230a0002 0x519e230a 0x2519f 0x230a0002 0x51a0230a 0x251a1 0x230a0002 0x51a2230a 0x251a3 0x230a0002 0x51a4230a 0x251a5 0x230a0002 0x51a6230a 0x251a7 0x230a0002 0x51a8230a 0x251a9 0x230a0002 0x51aa230a 0x251ab 0x230a0002 0x51ac230a 0x251ad 0x230a0002 0x51ae230a 0x251af 0x230a0002 0x51b0230a 0x251b1 0x230a0002 0x51b2230a 0x251b3 0x230a0002 0x51b4230a 0x251b5 0x230a0002 0x51b6230a 0x251b7 0x230a0002 0x51b8230a 0x251b9 0x230a0002 0x51ba230a 0x251bb 0x230a0002 0x51bc230a 0x251bd 0x230a0002 0x51be230a 0x251bf 0x230a0002 0x51c0230a 0x251c1 0x230a0002 0x51c2230a 0x251c3 0x230a0002 0x51c4230a 0x251c5 0x230a0002 0x51c6230a 0x251c7 0x230a0002 0x51c8230a 0x251c9 0x230a0002 0x51ca230a 0x251cb 0x230a0002 0x51cc230a 0x251cd 0x230a0002 0x51ce230a 0x251cf 0x230a0002 0x51d0230a 0x251d1 0x230a0002 0x51d2230a 0x251d3 0x230a0002 0x51d4230a 0x251d5 0x230a0002 0x51d6230a 0x251d7 0x230a0002 0x51d8230a 0x251d9 0x230a0002 0x51da230a 0x251db 0x230a0002 0x51dc230a 0x251dd 0x230a0002 0x51de230a 0x251df 0x230a0002 0x51e0230a 0x251e1 0x230a0002 0x51e2230a 0x251e3 0x230a0002 0x51e4230a 0x251e5 0x230a0002 0x51e6230a 0x251e7 0x230a0002 0x51e8230a 0x251e9 0x230a0002 0x51ea230a 0x251eb 0x230a0002 0x51ec230a 0x251ed 0x230a0002 0x51ee230a 0x251ef 0x230a0002 0x51f0230a 0x251f1 0x230a0002 0x51f2230a 0x251f3 0x230a0002 0x51f4230a 0x251f5 0x230a0002 0x51f6230a 0x251f7 0x230a0002 0x51f8230a 0x251f9 0x230a0002 0x51fa230a 0x251fb 0x230a0002 0x51fc230a 0x251fd 0x230a0002 0x51fe230a 0x251ff>;
		};
	};

	mt107_lcd5300206: lcd5300206@5300206 {
		work-mode = <0x00>;
		bpp = <0x18>;
		lane-number = <0x01>;
		need-check-esd = <0x00>;
		esd-timeout = <0x7d0>;
		esd-check-reg = <0x0a>;
		esd-return-code = <0x9c>;
		fps = <0x3c>;
		width-mm = <0x44>;
		height-mm = <0x79>;
		panel-name = "lcd_co5300_oled206_mipi";
		power-on-sequence = <0x21 0x01 0x14 0x32 0x01 0x14 0x32 0x00 0x14 0x32 0x01 0x32>;
		power-off-sequence = <0x32 0x00 0x14 0x21 0x00 0x14>;
		init-data = [23 00 00 02 fe 20 23 00 00 02 f4 5a 23 00 00 02 f5 59 23 00 00 02 fe 40 23 00 00 02 5d 24 23 00 00 02 60 08 23 00 00 02 61 02 23 00 00 02 62 03 23 00 00 02 0c d7 23 00 00 02 0d f0 23 00 00 02 fe d0 23 00 00 02 2a 80 23 00 00 02 2b 02 23 00 00 02 fe 90 23 00 00 02 4e 1f 23 00 00 02 fe 00 23 00 00 02 35 00 23 00 00 02 3a 77 23 00 00 02 53 20 23 00 00 02 51 00 23 00 00 02 63 ff 29 00 00 05 2a 00 16 01 b1 29 00 00 05 2b 00 00 01 f5 13 78 00 01 11 13 14 00 01 29];
		aod-in = [23 00 00 02 fe 00 13 0a 00 01 39];
		aod-out = [23 00 00 02 fe 00 13 0a 00 01 38];
		sleep-in = [13 0a 00 01 28 13 78 00 01 10];
		sleep-out = [13 78 00 01 11 13 32 00 01 29];

		display-timings {
			clock-frequency = <0x63da8>;
			hactive = <0x19c>;
			vactive = <0x1f6>;
			hback-porch = <0x18>;
			hfront-porch = <0x10>;
			hsync-len = <0x04>;
			vfront-porch = <0x09>;
			vback-porch = <0x08>;
			vsync-len = <0x01>;
		};

		oled-backlight {
			default-brightness = <0x78>;
			max-level = <0xff>;
			brightness-levels = <0x230a0002 0x5100230a 0x25101 0x230a0002 0x5102230a 0x25103 0x230a0002 0x5104230a 0x25105 0x230a0002 0x5106230a 0x25107 0x230a0002 0x5108230a 0x25109 0x230a0002 0x510a230a 0x2510b 0x230a0002 0x510c230a 0x2510d 0x230a0002 0x510e230a 0x2510f 0x230a0002 0x5110230a 0x25111 0x230a0002 0x5112230a 0x25113 0x230a0002 0x5114230a 0x25115 0x230a0002 0x5116230a 0x25117 0x230a0002 0x5118230a 0x25119 0x230a0002 0x511a230a 0x2511b 0x230a0002 0x511c230a 0x2511d 0x230a0002 0x511e230a 0x2511f 0x230a0002 0x5120230a 0x25121 0x230a0002 0x5122230a 0x25123 0x230a0002 0x5124230a 0x25125 0x230a0002 0x5126230a 0x25127 0x230a0002 0x5128230a 0x25129 0x230a0002 0x512a230a 0x2512b 0x230a0002 0x512c230a 0x2512d 0x230a0002 0x512e230a 0x2512f 0x230a0002 0x5130230a 0x25131 0x230a0002 0x5132230a 0x25133 0x230a0002 0x5134230a 0x25135 0x230a0002 0x5136230a 0x25137 0x230a0002 0x5138230a 0x25139 0x230a0002 0x513a230a 0x2513b 0x230a0002 0x513c230a 0x2513d 0x230a0002 0x513e230a 0x2513f 0x230a0002 0x5140230a 0x25141 0x230a0002 0x5142230a 0x25143 0x230a0002 0x5144230a 0x25145 0x230a0002 0x5146230a 0x25147 0x230a0002 0x5148230a 0x25149 0x230a0002 0x514a230a 0x2514b 0x230a0002 0x514c230a 0x2514d 0x230a0002 0x514e230a 0x2514f 0x230a0002 0x5150230a 0x25151 0x230a0002 0x5152230a 0x25153 0x230a0002 0x5154230a 0x25155 0x230a0002 0x5156230a 0x25157 0x230a0002 0x5158230a 0x25159 0x230a0002 0x515a230a 0x2515b 0x230a0002 0x515c230a 0x2515d 0x230a0002 0x515e230a 0x2515f 0x230a0002 0x5160230a 0x25161 0x230a0002 0x5162230a 0x25163 0x230a0002 0x5164230a 0x25165 0x230a0002 0x5166230a 0x25167 0x230a0002 0x5168230a 0x25169 0x230a0002 0x516a230a 0x2516b 0x230a0002 0x516c230a 0x2516d 0x230a0002 0x516e230a 0x2516f 0x230a0002 0x5170230a 0x25171 0x230a0002 0x5172230a 0x25173 0x230a0002 0x5174230a 0x25175 0x230a0002 0x5176230a 0x25177 0x230a0002 0x5178230a 0x25179 0x230a0002 0x517a230a 0x2517b 0x230a0002 0x517c230a 0x2517d 0x230a0002 0x517e230a 0x2517f 0x230a0002 0x5180230a 0x25181 0x230a0002 0x5182230a 0x25183 0x230a0002 0x5184230a 0x25185 0x230a0002 0x5186230a 0x25187 0x230a0002 0x5188230a 0x25189 0x230a0002 0x518a230a 0x2518b 0x230a0002 0x518c230a 0x2518d 0x230a0002 0x518e230a 0x2518f 0x230a0002 0x5190230a 0x25191 0x230a0002 0x5192230a 0x25193 0x230a0002 0x5194230a 0x25195 0x230a0002 0x5196230a 0x25197 0x230a0002 0x5198230a 0x25199 0x230a0002 0x519a230a 0x2519b 0x230a0002 0x519c230a 0x2519d 0x230a0002 0x519e230a 0x2519f 0x230a0002 0x51a0230a 0x251a1 0x230a0002 0x51a2230a 0x251a3 0x230a0002 0x51a4230a 0x251a5 0x230a0002 0x51a6230a 0x251a7 0x230a0002 0x51a8230a 0x251a9 0x230a0002 0x51aa230a 0x251ab 0x230a0002 0x51ac230a 0x251ad 0x230a0002 0x51ae230a 0x251af 0x230a0002 0x51b0230a 0x251b1 0x230a0002 0x51b2230a 0x251b3 0x230a0002 0x51b4230a 0x251b5 0x230a0002 0x51b6230a 0x251b7 0x230a0002 0x51b8230a 0x251b9 0x230a0002 0x51ba230a 0x251bb 0x230a0002 0x51bc230a 0x251bd 0x230a0002 0x51be230a 0x251bf 0x230a0002 0x51c0230a 0x251c1 0x230a0002 0x51c2230a 0x251c3 0x230a0002 0x51c4230a 0x251c5 0x230a0002 0x51c6230a 0x251c7 0x230a0002 0x51c8230a 0x251c9 0x230a0002 0x51ca230a 0x251cb 0x230a0002 0x51cc230a 0x251cd 0x230a0002 0x51ce230a 0x251cf 0x230a0002 0x51d0230a 0x251d1 0x230a0002 0x51d2230a 0x251d3 0x230a0002 0x51d4230a 0x251d5 0x230a0002 0x51d6230a 0x251d7 0x230a0002 0x51d8230a 0x251d9 0x230a0002 0x51da230a 0x251db 0x230a0002 0x51dc230a 0x251dd 0x230a0002 0x51de230a 0x251df 0x230a0002 0x51e0230a 0x251e1 0x230a0002 0x51e2230a 0x251e3 0x230a0002 0x51e4230a 0x251e5 0x230a0002 0x51e6230a 0x251e7 0x230a0002 0x51e8230a 0x251e9 0x230a0002 0x51ea230a 0x251eb 0x230a0002 0x51ec230a 0x251ed 0x230a0002 0x51ee230a 0x251ef 0x230a0002 0x51f0230a 0x251f1 0x230a0002 0x51f2230a 0x251f3 0x230a0002 0x51f4230a 0x251f5 0x230a0002 0x51f6230a 0x251f7 0x230a0002 0x51f8230a 0x251f9 0x230a0002 0x51fa230a 0x251fb 0x230a0002 0x51fc230a 0x251fd 0x230a0002 0x51fe230a 0x251ff>;
		};
	};

	mt107_lcd5300213: lcd5300213@5300213 {
		work-mode = <0x00>;
		bpp = <0x18>;
		lane-number = <0x01>;
		need-check-esd = <0x00>;
		esd-timeout = <0x7d0>;
		esd-check-reg = <0x0a>;
		esd-return-code = <0x9c>;
		fps = <0x3c>;
		width-mm = <0x44>;
		height-mm = <0x79>;
		panel-name = "lcd_co5300_oled213_mipi";
		power-on-sequence = <0x21 0x01 0x14 0x32 0x01 0x14 0x32 0x00 0x14 0x32 0x01 0x32>;
		power-off-sequence = <0x32 0x00 0x14 0x21 0x00 0x14>;
		init-data = [23 00 00 02 fe 20 23 00 00 02 f4 5a 23 00 00 02 f5 59 23 00 00 02 fe e0 23 00 00 02 04 20 23 00 00 02 fe 00 23 00 00 02 35 00 23 00 00 02 3a 77 23 00 00 02 53 20 23 00 00 02 51 00 23 00 00 02 63 ff 29 00 00 05 2a 00 15 01 b0 29 00 00 05 2b 00 00 01 f5 13 78 00 01 11 13 14 00 01 29];
		aod-in = [23 00 00 02 fe 00 13 0a 00 01 39];
		aod-out = [23 00 00 02 fe 00 13 0a 00 01 38];
		sleep-in = [13 0a 00 01 28 13 78 00 01 10];
		sleep-out = [13 78 00 01 11 13 32 00 01 29];

		display-timings {
			clock-frequency = <0x704e0>;
			hactive = <0x19c>;
			vactive = <0x1f6>;
			hback-porch = <0x12>;
			hfront-porch = <0x1e>;
			hsync-len = <0x02>;
			vfront-porch = <0x06>;
			vback-porch = <0x07>;
			vsync-len = <0x01>;
		};

		oled-backlight {
			default-brightness = <0x19>;
			max-level = <0xff>;
			brightness-levels = <0x230a0002 0x5100230a 0x25101 0x230a0002 0x5102230a 0x25103 0x230a0002 0x5104230a 0x25105 0x230a0002 0x5106230a 0x25107 0x230a0002 0x5108230a 0x25109 0x230a0002 0x510a230a 0x2510b 0x230a0002 0x510c230a 0x2510d 0x230a0002 0x510e230a 0x2510f 0x230a0002 0x5110230a 0x25111 0x230a0002 0x5112230a 0x25113 0x230a0002 0x5114230a 0x25115 0x230a0002 0x5116230a 0x25117 0x230a0002 0x5118230a 0x25119 0x230a0002 0x511a230a 0x2511b 0x230a0002 0x511c230a 0x2511d 0x230a0002 0x511e230a 0x2511f 0x230a0002 0x5120230a 0x25121 0x230a0002 0x5122230a 0x25123 0x230a0002 0x5124230a 0x25125 0x230a0002 0x5126230a 0x25127 0x230a0002 0x5128230a 0x25129 0x230a0002 0x512a230a 0x2512b 0x230a0002 0x512c230a 0x2512d 0x230a0002 0x512e230a 0x2512f 0x230a0002 0x5130230a 0x25131 0x230a0002 0x5132230a 0x25133 0x230a0002 0x5134230a 0x25135 0x230a0002 0x5136230a 0x25137 0x230a0002 0x5138230a 0x25139 0x230a0002 0x513a230a 0x2513b 0x230a0002 0x513c230a 0x2513d 0x230a0002 0x513e230a 0x2513f 0x230a0002 0x5140230a 0x25141 0x230a0002 0x5142230a 0x25143 0x230a0002 0x5144230a 0x25145 0x230a0002 0x5146230a 0x25147 0x230a0002 0x5148230a 0x25149 0x230a0002 0x514a230a 0x2514b 0x230a0002 0x514c230a 0x2514d 0x230a0002 0x514e230a 0x2514f 0x230a0002 0x5150230a 0x25151 0x230a0002 0x5152230a 0x25153 0x230a0002 0x5154230a 0x25155 0x230a0002 0x5156230a 0x25157 0x230a0002 0x5158230a 0x25159 0x230a0002 0x515a230a 0x2515b 0x230a0002 0x515c230a 0x2515d 0x230a0002 0x515e230a 0x2515f 0x230a0002 0x5160230a 0x25161 0x230a0002 0x5162230a 0x25163 0x230a0002 0x5164230a 0x25165 0x230a0002 0x5166230a 0x25167 0x230a0002 0x5168230a 0x25169 0x230a0002 0x516a230a 0x2516b 0x230a0002 0x516c230a 0x2516d 0x230a0002 0x516e230a 0x2516f 0x230a0002 0x5170230a 0x25171 0x230a0002 0x5172230a 0x25173 0x230a0002 0x5174230a 0x25175 0x230a0002 0x5176230a 0x25177 0x230a0002 0x5178230a 0x25179 0x230a0002 0x517a230a 0x2517b 0x230a0002 0x517c230a 0x2517d 0x230a0002 0x517e230a 0x2517f 0x230a0002 0x5180230a 0x25181 0x230a0002 0x5182230a 0x25183 0x230a0002 0x5184230a 0x25185 0x230a0002 0x5186230a 0x25187 0x230a0002 0x5188230a 0x25189 0x230a0002 0x518a230a 0x2518b 0x230a0002 0x518c230a 0x2518d 0x230a0002 0x518e230a 0x2518f 0x230a0002 0x5190230a 0x25191 0x230a0002 0x5192230a 0x25193 0x230a0002 0x5194230a 0x25195 0x230a0002 0x5196230a 0x25197 0x230a0002 0x5198230a 0x25199 0x230a0002 0x519a230a 0x2519b 0x230a0002 0x519c230a 0x2519d 0x230a0002 0x519e230a 0x2519f 0x230a0002 0x51a0230a 0x251a1 0x230a0002 0x51a2230a 0x251a3 0x230a0002 0x51a4230a 0x251a5 0x230a0002 0x51a6230a 0x251a7 0x230a0002 0x51a8230a 0x251a9 0x230a0002 0x51aa230a 0x251ab 0x230a0002 0x51ac230a 0x251ad 0x230a0002 0x51ae230a 0x251af 0x230a0002 0x51b0230a 0x251b1 0x230a0002 0x51b2230a 0x251b3 0x230a0002 0x51b4230a 0x251b5 0x230a0002 0x51b6230a 0x251b7 0x230a0002 0x51b8230a 0x251b9 0x230a0002 0x51ba230a 0x251bb 0x230a0002 0x51bc230a 0x251bd 0x230a0002 0x51be230a 0x251bf 0x230a0002 0x51c0230a 0x251c1 0x230a0002 0x51c2230a 0x251c3 0x230a0002 0x51c4230a 0x251c5 0x230a0002 0x51c6230a 0x251c7 0x230a0002 0x51c8230a 0x251c9 0x230a0002 0x51ca230a 0x251cb 0x230a0002 0x51cc230a 0x251cd 0x230a0002 0x51ce230a 0x251cf 0x230a0002 0x51d0230a 0x251d1 0x230a0002 0x51d2230a 0x251d3 0x230a0002 0x51d4230a 0x251d5 0x230a0002 0x51d6230a 0x251d7 0x230a0002 0x51d8230a 0x251d9 0x230a0002 0x51da230a 0x251db 0x230a0002 0x51dc230a 0x251dd 0x230a0002 0x51de230a 0x251df 0x230a0002 0x51e0230a 0x251e1 0x230a0002 0x51e2230a 0x251e3 0x230a0002 0x51e4230a 0x251e5 0x230a0002 0x51e6230a 0x251e7 0x230a0002 0x51e8230a 0x251e9 0x230a0002 0x51ea230a 0x251eb 0x230a0002 0x51ec230a 0x251ed 0x230a0002 0x51ee230a 0x251ef 0x230a0002 0x51f0230a 0x251f1 0x230a0002 0x51f2230a 0x251f3 0x230a0002 0x51f4230a 0x251f5 0x230a0002 0x51f6230a 0x251f7 0x230a0002 0x51f8230a 0x251f9 0x230a0002 0x51fa230a 0x251fb 0x230a0002 0x51fc230a 0x251fd 0x230a0002 0x51fe230a 0x251ff>;
		};
	};

	mt107_lcd13613213: lcd13613213@13613213 {
		work-mode = <0x00>;
		bpp = <0x18>;
		lane-number = <0x01>;
		need-check-esd = <0x00>;
		esd-timeout = <0x7d0>;
		esd-check-reg = <0x0a>;
		esd-return-code = <0x9c>;
		fps = <0x3c>;
		width-mm = <0x44>;
		height-mm = <0x79>;
		panel-name = "lcd_ch13613_oled213_mipi";
		power-on-sequence = <0x21 0x01 0x14 0x32 0x01 0x14 0x32 0x00 0x14 0x32 0x01 0x32>;
		power-off-sequence = <0x32 0x00 0x14 0x21 0x00 0x14>;
		init-data = <0x29000005 0x2a000401 0x9f290000 0x52b0000 0x1f52300 0x23a77 0x23000002 0x35002300 0x2535a 0x23000002 0x51001378 0x11113 0x32000129>;
		sleep-in = [13 0a 00 01 28 13 78 00 01 10];
		sleep-out = [13 78 00 01 11 13 32 00 01 29];

		display-timings {
			clock-frequency = <0x704e0>;
			hactive = <0x19c>;
			vactive = <0x1f6>;
			hback-porch = <0x12>;
			hfront-porch = <0x30>;
			hsync-len = <0x02>;
			vfront-porch = <0x1e>;
			vback-porch = <0x18>;
			vsync-len = <0x02>;
		};

		oled-backlight {
			default-brightness = <0x78>;
			max-level = <0xff>;
			brightness-levels = <0x230a0002 0x5100230a 0x25101 0x230a0002 0x5102230a 0x25103 0x230a0002 0x5104230a 0x25105 0x230a0002 0x5106230a 0x25107 0x230a0002 0x5108230a 0x25109 0x230a0002 0x510a230a 0x2510b 0x230a0002 0x510c230a 0x2510d 0x230a0002 0x510e230a 0x2510f 0x230a0002 0x5110230a 0x25111 0x230a0002 0x5112230a 0x25113 0x230a0002 0x5114230a 0x25115 0x230a0002 0x5116230a 0x25117 0x230a0002 0x5118230a 0x25119 0x230a0002 0x511a230a 0x2511b 0x230a0002 0x511c230a 0x2511d 0x230a0002 0x511e230a 0x2511f 0x230a0002 0x5120230a 0x25121 0x230a0002 0x5122230a 0x25123 0x230a0002 0x5124230a 0x25125 0x230a0002 0x5126230a 0x25127 0x230a0002 0x5128230a 0x25129 0x230a0002 0x512a230a 0x2512b 0x230a0002 0x512c230a 0x2512d 0x230a0002 0x512e230a 0x2512f 0x230a0002 0x5130230a 0x25131 0x230a0002 0x5132230a 0x25133 0x230a0002 0x5134230a 0x25135 0x230a0002 0x5136230a 0x25137 0x230a0002 0x5138230a 0x25139 0x230a0002 0x513a230a 0x2513b 0x230a0002 0x513c230a 0x2513d 0x230a0002 0x513e230a 0x2513f 0x230a0002 0x5140230a 0x25141 0x230a0002 0x5142230a 0x25143 0x230a0002 0x5144230a 0x25145 0x230a0002 0x5146230a 0x25147 0x230a0002 0x5148230a 0x25149 0x230a0002 0x514a230a 0x2514b 0x230a0002 0x514c230a 0x2514d 0x230a0002 0x514e230a 0x2514f 0x230a0002 0x5150230a 0x25151 0x230a0002 0x5152230a 0x25153 0x230a0002 0x5154230a 0x25155 0x230a0002 0x5156230a 0x25157 0x230a0002 0x5158230a 0x25159 0x230a0002 0x515a230a 0x2515b 0x230a0002 0x515c230a 0x2515d 0x230a0002 0x515e230a 0x2515f 0x230a0002 0x5160230a 0x25161 0x230a0002 0x5162230a 0x25163 0x230a0002 0x5164230a 0x25165 0x230a0002 0x5166230a 0x25167 0x230a0002 0x5168230a 0x25169 0x230a0002 0x516a230a 0x2516b 0x230a0002 0x516c230a 0x2516d 0x230a0002 0x516e230a 0x2516f 0x230a0002 0x5170230a 0x25171 0x230a0002 0x5172230a 0x25173 0x230a0002 0x5174230a 0x25175 0x230a0002 0x5176230a 0x25177 0x230a0002 0x5178230a 0x25179 0x230a0002 0x517a230a 0x2517b 0x230a0002 0x517c230a 0x2517d 0x230a0002 0x517e230a 0x2517f 0x230a0002 0x5180230a 0x25181 0x230a0002 0x5182230a 0x25183 0x230a0002 0x5184230a 0x25185 0x230a0002 0x5186230a 0x25187 0x230a0002 0x5188230a 0x25189 0x230a0002 0x518a230a 0x2518b 0x230a0002 0x518c230a 0x2518d 0x230a0002 0x518e230a 0x2518f 0x230a0002 0x5190230a 0x25191 0x230a0002 0x5192230a 0x25193 0x230a0002 0x5194230a 0x25195 0x230a0002 0x5196230a 0x25197 0x230a0002 0x5198230a 0x25199 0x230a0002 0x519a230a 0x2519b 0x230a0002 0x519c230a 0x2519d 0x230a0002 0x519e230a 0x2519f 0x230a0002 0x51a0230a 0x251a1 0x230a0002 0x51a2230a 0x251a3 0x230a0002 0x51a4230a 0x251a5 0x230a0002 0x51a6230a 0x251a7 0x230a0002 0x51a8230a 0x251a9 0x230a0002 0x51aa230a 0x251ab 0x230a0002 0x51ac230a 0x251ad 0x230a0002 0x51ae230a 0x251af 0x230a0002 0x51b0230a 0x251b1 0x230a0002 0x51b2230a 0x251b3 0x230a0002 0x51b4230a 0x251b5 0x230a0002 0x51b6230a 0x251b7 0x230a0002 0x51b8230a 0x251b9 0x230a0002 0x51ba230a 0x251bb 0x230a0002 0x51bc230a 0x251bd 0x230a0002 0x51be230a 0x251bf 0x230a0002 0x51c0230a 0x251c1 0x230a0002 0x51c2230a 0x251c3 0x230a0002 0x51c4230a 0x251c5 0x230a0002 0x51c6230a 0x251c7 0x230a0002 0x51c8230a 0x251c9 0x230a0002 0x51ca230a 0x251cb 0x230a0002 0x51cc230a 0x251cd 0x230a0002 0x51ce230a 0x251cf 0x230a0002 0x51d0230a 0x251d1 0x230a0002 0x51d2230a 0x251d3 0x230a0002 0x51d4230a 0x251d5 0x230a0002 0x51d6230a 0x251d7 0x230a0002 0x51d8230a 0x251d9 0x230a0002 0x51da230a 0x251db 0x230a0002 0x51dc230a 0x251dd 0x230a0002 0x51de230a 0x251df 0x230a0002 0x51e0230a 0x251e1 0x230a0002 0x51e2230a 0x251e3 0x230a0002 0x51e4230a 0x251e5 0x230a0002 0x51e6230a 0x251e7 0x230a0002 0x51e8230a 0x251e9 0x230a0002 0x51ea230a 0x251eb 0x230a0002 0x51ec230a 0x251ed 0x230a0002 0x51ee230a 0x251ef 0x230a0002 0x51f0230a 0x251f1 0x230a0002 0x51f2230a 0x251f3 0x230a0002 0x51f4230a 0x251f5 0x230a0002 0x51f6230a 0x251f7 0x230a0002 0x51f8230a 0x251f9 0x230a0002 0x51fa230a 0x251fb 0x230a0002 0x51fc230a 0x251fd 0x230a0002 0x51fe230a 0x251ff>;
		};
	};

	mt107_lcd3311148: lcd3311148@3311148 {
		work-mode = <0x00>;
		bpp = <0x18>;
		lane-number = <0x01>;
		need-check-esd = <0x00>;
		esd-timeout = <0x7d0>;
		esd-check-reg = <0x0a>;
		esd-return-code = <0x9c>;
		fps = <0x3c>;
		width-mm = <0x44>;
		height-mm = <0x79>;
		panel-name = "lcd_icna3311_oled148_mipi";
		power-on-sequence = <0x21 0x01 0x14 0x32 0x01 0x14 0x32 0x00 0x14 0x32 0x01 0x32>;
		power-off-sequence = <0x32 0x00 0x14 0x21 0x00 0x14>;
		init-data = <0x23000002 0xfe002300 0x23a77 0x23000002 0x35002300 0x25320 0x23000002 0x51482300 0x263ff 0x29000005 0x2a000001 0xdf290000 0x52b0000 0x1df1378 0x11113 0x14000129>;
		sleep-in = [13 0a 00 01 28 13 78 00 01 10];
		sleep-out = [13 78 00 01 11 13 32 00 01 29];

		display-timings {
			clock-frequency = <0x704e0>;
			hactive = <0x1e0>;
			vactive = <0x1e0>;
			hback-porch = <0x18>;
			hfront-porch = <0x20>;
			hsync-len = <0x04>;
			vfront-porch = <0x08>;
			vback-porch = <0x04>;
			vsync-len = <0x02>;
		};

		oled-backlight {
			default-brightness = <0x78>;
			max-level = <0xff>;
			brightness-levels = <0x230a0002 0x5100230a 0x25101 0x230a0002 0x5102230a 0x25103 0x230a0002 0x5104230a 0x25105 0x230a0002 0x5106230a 0x25107 0x230a0002 0x5108230a 0x25109 0x230a0002 0x510a230a 0x2510b 0x230a0002 0x510c230a 0x2510d 0x230a0002 0x510e230a 0x2510f 0x230a0002 0x5110230a 0x25111 0x230a0002 0x5112230a 0x25113 0x230a0002 0x5114230a 0x25115 0x230a0002 0x5116230a 0x25117 0x230a0002 0x5118230a 0x25119 0x230a0002 0x511a230a 0x2511b 0x230a0002 0x511c230a 0x2511d 0x230a0002 0x511e230a 0x2511f 0x230a0002 0x5120230a 0x25121 0x230a0002 0x5122230a 0x25123 0x230a0002 0x5124230a 0x25125 0x230a0002 0x5126230a 0x25127 0x230a0002 0x5128230a 0x25129 0x230a0002 0x512a230a 0x2512b 0x230a0002 0x512c230a 0x2512d 0x230a0002 0x512e230a 0x2512f 0x230a0002 0x5130230a 0x25131 0x230a0002 0x5132230a 0x25133 0x230a0002 0x5134230a 0x25135 0x230a0002 0x5136230a 0x25137 0x230a0002 0x5138230a 0x25139 0x230a0002 0x513a230a 0x2513b 0x230a0002 0x513c230a 0x2513d 0x230a0002 0x513e230a 0x2513f 0x230a0002 0x5140230a 0x25141 0x230a0002 0x5142230a 0x25143 0x230a0002 0x5144230a 0x25145 0x230a0002 0x5146230a 0x25147 0x230a0002 0x5148230a 0x25149 0x230a0002 0x514a230a 0x2514b 0x230a0002 0x514c230a 0x2514d 0x230a0002 0x514e230a 0x2514f 0x230a0002 0x5150230a 0x25151 0x230a0002 0x5152230a 0x25153 0x230a0002 0x5154230a 0x25155 0x230a0002 0x5156230a 0x25157 0x230a0002 0x5158230a 0x25159 0x230a0002 0x515a230a 0x2515b 0x230a0002 0x515c230a 0x2515d 0x230a0002 0x515e230a 0x2515f 0x230a0002 0x5160230a 0x25161 0x230a0002 0x5162230a 0x25163 0x230a0002 0x5164230a 0x25165 0x230a0002 0x5166230a 0x25167 0x230a0002 0x5168230a 0x25169 0x230a0002 0x516a230a 0x2516b 0x230a0002 0x516c230a 0x2516d 0x230a0002 0x516e230a 0x2516f 0x230a0002 0x5170230a 0x25171 0x230a0002 0x5172230a 0x25173 0x230a0002 0x5174230a 0x25175 0x230a0002 0x5176230a 0x25177 0x230a0002 0x5178230a 0x25179 0x230a0002 0x517a230a 0x2517b 0x230a0002 0x517c230a 0x2517d 0x230a0002 0x517e230a 0x2517f 0x230a0002 0x5180230a 0x25181 0x230a0002 0x5182230a 0x25183 0x230a0002 0x5184230a 0x25185 0x230a0002 0x5186230a 0x25187 0x230a0002 0x5188230a 0x25189 0x230a0002 0x518a230a 0x2518b 0x230a0002 0x518c230a 0x2518d 0x230a0002 0x518e230a 0x2518f 0x230a0002 0x5190230a 0x25191 0x230a0002 0x5192230a 0x25193 0x230a0002 0x5194230a 0x25195 0x230a0002 0x5196230a 0x25197 0x230a0002 0x5198230a 0x25199 0x230a0002 0x519a230a 0x2519b 0x230a0002 0x519c230a 0x2519d 0x230a0002 0x519e230a 0x2519f 0x230a0002 0x51a0230a 0x251a1 0x230a0002 0x51a2230a 0x251a3 0x230a0002 0x51a4230a 0x251a5 0x230a0002 0x51a6230a 0x251a7 0x230a0002 0x51a8230a 0x251a9 0x230a0002 0x51aa230a 0x251ab 0x230a0002 0x51ac230a 0x251ad 0x230a0002 0x51ae230a 0x251af 0x230a0002 0x51b0230a 0x251b1 0x230a0002 0x51b2230a 0x251b3 0x230a0002 0x51b4230a 0x251b5 0x230a0002 0x51b6230a 0x251b7 0x230a0002 0x51b8230a 0x251b9 0x230a0002 0x51ba230a 0x251bb 0x230a0002 0x51bc230a 0x251bd 0x230a0002 0x51be230a 0x251bf 0x230a0002 0x51c0230a 0x251c1 0x230a0002 0x51c2230a 0x251c3 0x230a0002 0x51c4230a 0x251c5 0x230a0002 0x51c6230a 0x251c7 0x230a0002 0x51c8230a 0x251c9 0x230a0002 0x51ca230a 0x251cb 0x230a0002 0x51cc230a 0x251cd 0x230a0002 0x51ce230a 0x251cf 0x230a0002 0x51d0230a 0x251d1 0x230a0002 0x51d2230a 0x251d3 0x230a0002 0x51d4230a 0x251d5 0x230a0002 0x51d6230a 0x251d7 0x230a0002 0x51d8230a 0x251d9 0x230a0002 0x51da230a 0x251db 0x230a0002 0x51dc230a 0x251dd 0x230a0002 0x51de230a 0x251df 0x230a0002 0x51e0230a 0x251e1 0x230a0002 0x51e2230a 0x251e3 0x230a0002 0x51e4230a 0x251e5 0x230a0002 0x51e6230a 0x251e7 0x230a0002 0x51e8230a 0x251e9 0x230a0002 0x51ea230a 0x251eb 0x230a0002 0x51ec230a 0x251ed 0x230a0002 0x51ee230a 0x251ef 0x230a0002 0x51f0230a 0x251f1 0x230a0002 0x51f2230a 0x251f3 0x230a0002 0x51f4230a 0x251f5 0x230a0002 0x51f6230a 0x251f7 0x230a0002 0x51f8230a 0x251f9 0x230a0002 0x51fa230a 0x251fb 0x230a0002 0x51fc230a 0x251fd 0x230a0002 0x51fe230a 0x251ff>;
		};
	};

	mt107_lcdffff: lcdffff@ffff {
		work-mode = <0x01>;
		bpp = <0x18>;
		lane-number = <0x04>;
		fps = <0x3c>;
		panel-name = "lcd_dummy_mipi_hd";
		power-on-sequence = <0x7e 0x01 0x14 0x7e 0x00 0x14 0x7e 0x01 0x78>;
		power-off-sequence = <0x7e 0x00 0x14>;
		init-data = [13 78 00 01 11 13 64 00 01 29];
		sleep-in = [13 0a 00 01 28 13 78 00 01 10];
		sleep-out = [13 78 00 01 11 13 64 00 01 29];

		display-timings {
			clock-frequency = <0x7a120>;
			hactive = <0x2d0>;
			vactive = <0x500>;
			hback-porch = <0x1e>;
			hfront-porch = <0x28>;
			vback-porch = <0x06>;
			vfront-porch = <0x14>;
			hsync-len = <0x1e>;
			vsync-len = <0x04>;
		};
	};
